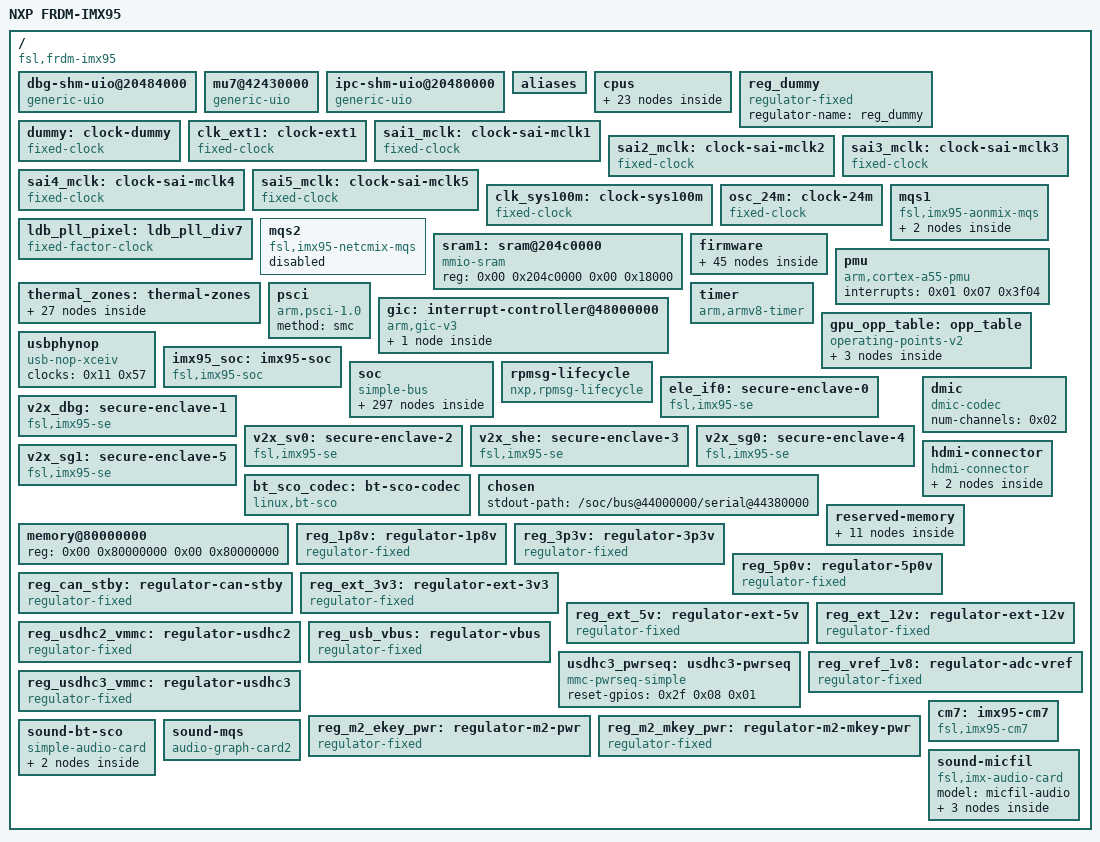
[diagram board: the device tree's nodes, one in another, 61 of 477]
/dts-v1/;

/ {
	interrupt-parent = <0x01>;
	#address-cells = <0x02>;
	#size-cells = <0x02>;
	compatible = "fsl,frdm-imx95", "fsl,imx95";
	model = "NXP FRDM-IMX95";

	dbg-shm-uio@20484000 {
		status = "okay";
		reg = <0x00 0x20484000 0x00 0x2000>;
		memory-region = <0x14f>;
		compatible = "generic-uio";
	};

	mu7@42430000 {
		status = "okay";
		interrupts = <0x00 0xea 0x04>;
		interrupt-parent = <0x01>;
		reg = <0x00 0x42430000 0x00 0x20000>;
		compatible = "generic-uio";
	};

	ipc-shm-uio@20480000 {
		status = "okay";
		reg = <0x00 0x20480000 0x00 0x4000>;
		memory-region = <0x14e>;
		compatible = "generic-uio";
	};

	aliases {
		gpio0 = "/soc/gpio@47400000";
		gpio1 = "/soc/gpio@43810000";
		gpio2 = "/soc/gpio@43820000";
		gpio3 = "/soc/gpio@43840000";
		gpio4 = "/soc/gpio@43850000";
		i2c0 = "/soc/bus@44000000/i2c@44340000";
		i2c1 = "/soc/bus@44000000/i2c@44350000";
		i2c2 = "/soc/bus@42000000/i2c@42530000";
		i2c3 = "/soc/bus@42000000/i2c@42540000";
		i2c4 = "/soc/bus@42000000/i2c@426b0000";
		i2c5 = "/soc/bus@42000000/i2c@426c0000";
		i2c6 = "/soc/bus@42000000/i2c@426d0000";
		i2c7 = "/soc/bus@42000000/i2c@426e0000";
		mmc0 = "/soc/bus@42800000/mmc@42850000";
		mmc1 = "/soc/bus@42800000/mmc@42860000";
		mmc2 = "/soc/bus@42800000/mmc@428b0000";
		serial0 = "/soc/bus@44000000/serial@44380000";
		serial1 = "/soc/bus@44000000/serial@44390000";
		serial2 = "/soc/bus@42000000/serial@42570000";
		serial3 = "/soc/bus@42000000/serial@42580000";
		serial4 = "/soc/bus@42000000/serial@42590000";
		serial5 = "/soc/bus@42000000/serial@425a0000";
		serial6 = "/soc/bus@42000000/serial@42690000";
		serial7 = "/soc/bus@42000000/serial@426a0000";
		ethernet0 = "/soc/system-controller@4cde0000/pcie@4ca00000/ethernet@0,0";
		ethernet1 = "/soc/system-controller@4cde0000/pcie@4ca00000/ethernet@8,0";
	};

	cpus {
		#address-cells = <0x01>;
		#size-cells = <0x00>;

		idle-states {
			entry-method = "psci";

			cpu_pd_wait: cpu-pd-wait {
				compatible = "arm,idle-state";
				arm,psci-suspend-param = <0x10033>;
				local-timer-stop;
				entry-latency-us = <0x2710>;
				exit-latency-us = <0x1b58>;
				min-residency-us = <0x6978>;
				wakeup-latency-us = <0x3a98>;
				phandle = <0x02>;
			};
		};

		A55_0: cpu@0 {
			device_type = "cpu";
			compatible = "arm,cortex-a55";
			reg = <0x00>;
			enable-method = "psci";
			#cooling-cells = <0x02>;
			cpu-idle-states = <0x02>;
			power-domains = <0x03 0x08>;
			power-domain-names = "perf";
			i-cache-size = <0x8000>;
			i-cache-line-size = <0x40>;
			i-cache-sets = <0x80>;
			d-cache-size = <0x8000>;
			d-cache-line-size = <0x40>;
			d-cache-sets = <0x80>;
			next-level-cache = <0x04>;
			phandle = <0x0b>;
		};

		A55_1: cpu@100 {
			device_type = "cpu";
			compatible = "arm,cortex-a55";
			reg = <0x100>;
			enable-method = "psci";
			#cooling-cells = <0x02>;
			cpu-idle-states = <0x02>;
			power-domains = <0x03 0x08>;
			power-domain-names = "perf";
			i-cache-size = <0x8000>;
			i-cache-line-size = <0x40>;
			i-cache-sets = <0x80>;
			d-cache-size = <0x8000>;
			d-cache-line-size = <0x40>;
			d-cache-sets = <0x80>;
			next-level-cache = <0x05>;
			phandle = <0x0c>;
		};

		A55_2: cpu@200 {
			device_type = "cpu";
			compatible = "arm,cortex-a55";
			reg = <0x200>;
			enable-method = "psci";
			#cooling-cells = <0x02>;
			cpu-idle-states = <0x02>;
			power-domains = <0x03 0x08>;
			power-domain-names = "perf";
			i-cache-size = <0x8000>;
			i-cache-line-size = <0x40>;
			i-cache-sets = <0x80>;
			d-cache-size = <0x8000>;
			d-cache-line-size = <0x40>;
			d-cache-sets = <0x80>;
			next-level-cache = <0x06>;
			phandle = <0x0d>;
		};

		A55_3: cpu@300 {
			device_type = "cpu";
			compatible = "arm,cortex-a55";
			reg = <0x300>;
			enable-method = "psci";
			#cooling-cells = <0x02>;
			cpu-idle-states = <0x02>;
			power-domains = <0x03 0x08>;
			power-domain-names = "perf";
			i-cache-size = <0x8000>;
			i-cache-line-size = <0x40>;
			i-cache-sets = <0x80>;
			d-cache-size = <0x8000>;
			d-cache-line-size = <0x40>;
			d-cache-sets = <0x80>;
			next-level-cache = <0x07>;
			phandle = <0x0e>;
		};

		A55_4: cpu@400 {
			device_type = "cpu";
			compatible = "arm,cortex-a55";
			reg = <0x400>;
			power-domains = <0x03 0x08>;
			power-domain-names = "perf";
			enable-method = "psci";
			#cooling-cells = <0x02>;
			cpu-idle-states = <0x02>;
			i-cache-size = <0x8000>;
			i-cache-line-size = <0x40>;
			i-cache-sets = <0x80>;
			d-cache-size = <0x8000>;
			d-cache-line-size = <0x40>;
			d-cache-sets = <0x80>;
			next-level-cache = <0x08>;
			phandle = <0x0f>;
		};

		A55_5: cpu@500 {
			device_type = "cpu";
			compatible = "arm,cortex-a55";
			reg = <0x500>;
			power-domains = <0x03 0x08>;
			power-domain-names = "perf";
			enable-method = "psci";
			#cooling-cells = <0x02>;
			cpu-idle-states = <0x02>;
			i-cache-size = <0x8000>;
			i-cache-line-size = <0x40>;
			i-cache-sets = <0x80>;
			d-cache-size = <0x8000>;
			d-cache-line-size = <0x40>;
			d-cache-sets = <0x80>;
			next-level-cache = <0x09>;
			phandle = <0x10>;
		};

		l2_cache_l0: l2-cache-l0 {
			compatible = "cache";
			cache-size = <0x10000>;
			cache-line-size = <0x40>;
			cache-sets = <0x100>;
			cache-level = <0x02>;
			cache-unified;
			next-level-cache = <0x0a>;
			phandle = <0x04>;
		};

		l2_cache_l1: l2-cache-l1 {
			compatible = "cache";
			cache-size = <0x10000>;
			cache-line-size = <0x40>;
			cache-sets = <0x100>;
			cache-level = <0x02>;
			cache-unified;
			next-level-cache = <0x0a>;
			phandle = <0x05>;
		};

		l2_cache_l2: l2-cache-l2 {
			compatible = "cache";
			cache-size = <0x10000>;
			cache-line-size = <0x40>;
			cache-sets = <0x100>;
			cache-level = <0x02>;
			cache-unified;
			next-level-cache = <0x0a>;
			phandle = <0x06>;
		};

		l2_cache_l3: l2-cache-l3 {
			compatible = "cache";
			cache-size = <0x10000>;
			cache-line-size = <0x40>;
			cache-sets = <0x100>;
			cache-level = <0x02>;
			cache-unified;
			next-level-cache = <0x0a>;
			phandle = <0x07>;
		};

		l2_cache_l4: l2-cache-l4 {
			compatible = "cache";
			cache-size = <0x10000>;
			cache-line-size = <0x40>;
			cache-sets = <0x100>;
			cache-level = <0x02>;
			cache-unified;
			next-level-cache = <0x0a>;
			phandle = <0x08>;
		};

		l2_cache_l5: l2-cache-l5 {
			compatible = "cache";
			cache-size = <0x10000>;
			cache-line-size = <0x40>;
			cache-sets = <0x100>;
			cache-level = <0x02>;
			cache-unified;
			next-level-cache = <0x0a>;
			phandle = <0x09>;
		};

		l3_cache: l3-cache {
			compatible = "cache";
			cache-size = <0x80000>;
			cache-line-size = <0x40>;
			cache-sets = <0x200>;
			cache-level = <0x03>;
			cache-unified;
			phandle = <0x0a>;
		};

		cpu-map {

			cluster0 {

				core0 {
					cpu = <0x0b>;
				};

				core1 {
					cpu = <0x0c>;
				};

				core2 {
					cpu = <0x0d>;
				};

				core3 {
					cpu = <0x0e>;
				};

				core4 {
					cpu = <0x0f>;
				};

				core5 {
					cpu = <0x10>;
				};
			};
		};
	};

	reg_dummy: reg_dummy {
		compatible = "regulator-fixed";
		regulator-name = "reg_dummy";
		phandle = <0xa8>;
	};

	dummy: clock-dummy {
		compatible = "fixed-clock";
		#clock-cells = <0x00>;
		clock-frequency = <0x00>;
		clock-output-names = "dummy";
		phandle = <0x37>;
	};

	clk_ext1: clock-ext1 {
		compatible = "fixed-clock";
		#clock-cells = <0x00>;
		clock-frequency = <0x7ed6b40>;
		clock-output-names = "clk_ext1";
		phandle = <0xa9>;
	};

	sai1_mclk: clock-sai-mclk1 {
		compatible = "fixed-clock";
		#clock-cells = <0x00>;
		clock-frequency = <0x00>;
		clock-output-names = "sai1_mclk";
		phandle = <0xaa>;
	};

	sai2_mclk: clock-sai-mclk2 {
		compatible = "fixed-clock";
		#clock-cells = <0x00>;
		clock-frequency = <0x00>;
		clock-output-names = "sai2_mclk";
		phandle = <0xab>;
	};

	sai3_mclk: clock-sai-mclk3 {
		compatible = "fixed-clock";
		#clock-cells = <0x00>;
		clock-frequency = <0x00>;
		clock-output-names = "sai3_mclk";
		phandle = <0xac>;
	};

	sai4_mclk: clock-sai-mclk4 {
		compatible = "fixed-clock";
		#clock-cells = <0x00>;
		clock-frequency = <0x00>;
		clock-output-names = "sai4_mclk";
		phandle = <0xad>;
	};

	sai5_mclk: clock-sai-mclk5 {
		compatible = "fixed-clock";
		#clock-cells = <0x00>;
		clock-frequency = <0x00>;
		clock-output-names = "sai5_mclk";
		phandle = <0xae>;
	};

	clk_sys100m: clock-sys100m {
		compatible = "fixed-clock";
		#clock-cells = <0x00>;
		clock-frequency = <0x5f5e100>;
		clock-output-names = "clk_sys100m";
		phandle = <0x78>;
	};

	osc_24m: clock-24m {
		compatible = "fixed-clock";
		#clock-cells = <0x00>;
		clock-frequency = <0x16e3600>;
		clock-output-names = "osc_24m";
		phandle = <0x49>;
	};

	ldb_pll_pixel: ldb_pll_div7 {
		#clock-cells = <0x00>;
		compatible = "fixed-factor-clock";
		clocks = <0x11 0x26>;
		clock-div = <0x07>;
		clock-mult = <0x01>;
		clock-output-names = "ldb_pll_div7";
		phandle = <0x73>;
	};

	mqs1: mqs1 {
		compatible = "fsl,imx95-aonmix-mqs";
		status = "okay";
		pinctrl-names = "default";
		pinctrl-0 = <0x12>;
		clocks = <0x11 0x3a>;
		clock-names = "mclk";
		#sound-dai-cells = <0x00>;
		phandle = <0xaf>;

		mqs1_port: port {
			dai-format = "left_j";
			playback-only;
			phandle = <0xb0>;

			mqs1_endpoint: endpoint {
				remote-endpoint = <0x13>;
				phandle = <0x4e>;
			};
		};
	};

	mqs2: mqs2 {
		compatible = "fsl,imx95-netcmix-mqs";
		status = "disabled";
		phandle = <0xb1>;
	};

	sram1: sram@204c0000 {
		compatible = "mmio-sram";
		reg = <0x00 0x204c0000 0x00 0x18000>;
		ranges = <0x00 0x00 0x204c0000 0x18000>;
		#address-cells = <0x01>;
		#size-cells = <0x01>;
		phandle = <0x8c>;
	};

	firmware {

		scmi {
			compatible = "arm,scmi";
			mboxes = <0x14 0x05 0x00 0x14 0x03 0x00 0x14 0x03 0x01 0x14 0x05 0x01>;
			shmem = <0x15 0x16>;
			#address-cells = <0x01>;
			#size-cells = <0x00>;
			arm,max-rx-timeout-ms = <0x1388>;
			max-rx-timeout-ms = <0x1388>;

			scmi_devpd: protocol@11 {
				reg = <0x11>;
				#power-domain-cells = <0x01>;
				phandle = <0x51>;
			};

			scmi_sys_power: protocol@12 {
				reg = <0x12>;
				phandle = <0xb2>;
			};

			scmi_perf: protocol@13 {
				reg = <0x13>;
				#power-domain-cells = <0x01>;
				phandle = <0x03>;
			};

			scmi_clk: protocol@14 {
				reg = <0x14>;
				#clock-cells = <0x01>;
				phandle = <0x11>;
			};

			scmi_sensor: protocol@15 {
				reg = <0x15>;
				#thermal-sensor-cells = <0x01>;
				phandle = <0x18>;
			};

			scmi_iomuxc: protocol@19 {
				reg = <0x19>;
				pinctrl-names = "default";
				pinctrl-0 = <0x17>;
				phandle = <0x48>;

				pinctrl_hog: hoggrp {
					fsl,pins = <0x190 0x394 0x00 0x05 0x00 0x31e>;
					phandle = <0x17>;
				};

				pinctrl_flexcan2: flexcan2grp {
					fsl,pins = <0x74 0x278 0x00 0x02 0x00 0x39e 0x7c 0x280 0x444 0x02 0x02 0x39e>;
					phandle = <0x35>;
				};

				pinctrl_flexcan5: flexcan5grp {
					fsl,pins = <0x68 0x26c 0x00 0x03 0x00 0x39e 0x6c 0x270 0x450 0x03 0x00 0x39e>;
					phandle = <0x39>;
				};

				pinctrl_lpi2c1: lpi2c1grp {
					fsl,pins = <0x1c0 0x3c4 0x00 0x00 0x00 0x40000b9e 0x1c4 0x3c8 0x00 0x00 0x00 0x40000b9e>;
					phandle = <0xb3>;
				};

				pinctrl_lpi2c2: lpi2c2grp {
					fsl,pins = <0x1c8 0x3cc 0x00 0x00 0x00 0x40000b9e 0x1cc 0x3d0 0x00 0x00 0x00 0x40000b9e>;
					phandle = <0x4b>;
				};

				pinctrl_lpi2c3: lpi2c3grp {
					fsl,pins = <0x80 0x284 0x504 0x11 0x01 0x40000b9e 0x84 0x288 0x500 0x11 0x01 0x40000b9e>;
					phandle = <0x29>;
				};

				pinctrl_lpi2c4: lpi2c4grp {
					fsl,pins = <0x88 0x28c 0x50c 0x11 0x01 0x40000b9e 0x8c 0x290 0x508 0x11 0x01 0x40000b9e>;
					phandle = <0x2e>;
				};

				pinctrl_pcal6524: pcal6524grp {
					fsl,pins = <0x98 0x29c 0x00 0x00 0x00 0x31e>;
					phandle = <0x4c>;
				};

				pinctrl_uart1: uart1grp {
					fsl,pins = <0x1d0 0x3d4 0x00 0x00 0x00 0x31e 0x1d4 0x3d8 0x00 0x00 0x00 0x31e>;
					phandle = <0x4d>;
				};

				pinctrl_uart5: uart5grp {
					fsl,pins = <0x0c 0x210 0x574 0x06 0x00 0x31e 0x00 0x204 0x570 0x06 0x00 0x31e 0x04 0x208 0x00 0x06 0x00 0x31e 0x08 0x20c 0x56c 0x06 0x00 0x31e>;
					phandle = <0x34>;
				};

				pinctrl_enetc0: enetc0grp {
					fsl,pins = <0xc0 0x2c4 0x00 0x00 0x00 0x50e 0xc4 0x2c8 0x00 0x00 0x00 0x50e 0xc8 0x2cc 0x00 0x00 0x00 0x50e 0xcc 0x2d0 0x00 0x00 0x00 0x50e 0xd0 0x2d4 0x00 0x00 0x00 0x57e 0xd4 0x2d8 0x00 0x00 0x00 0x58e 0xd8 0x2dc 0x00 0x00 0x00 0x57e 0xdc 0x2e0 0x00 0x00 0x00 0x58e 0xe0 0x2e4 0x00 0x00 0x00 0x57e 0xe4 0x2e8 0x00 0x00 0x00 0x57e 0xe8 0x2ec 0x00 0x00 0x00 0x57e 0xec 0x2f0 0x00 0x00 0x00 0x57e>;
					phandle = <0x83>;
				};

				pinctrl_enetc1: enetc1grp {
					fsl,pins = <0xf8 0x2fc 0x00 0x00 0x00 0x50e 0xfc 0x300 0x00 0x00 0x00 0x50e 0x100 0x304 0x00 0x00 0x00 0x50e 0x104 0x308 0x00 0x00 0x00 0x50e 0x108 0x30c 0x00 0x00 0x00 0x57e 0x10c 0x310 0x00 0x00 0x00 0x58e 0x110 0x314 0x00 0x00 0x00 0x57e 0x114 0x318 0x00 0x00 0x00 0x58e 0x118 0x31c 0x00 0x00 0x00 0x57e 0x11c 0x320 0x00 0x00 0x00 0x57e 0x120 0x324 0x00 0x00 0x00 0x57e 0x124 0x328 0x00 0x00 0x00 0x57e>;
					phandle = <0x86>;
				};

				pinctrl_emdio: emdiogrp {
					fsl,pins = <0xf0 0x2f4 0x424 0x00 0x01 0x50e 0xf4 0x2f8 0x428 0x00 0x01 0x90e>;
					phandle = <0x89>;
				};

				pinctrl_mipi_dsi_csi: mipidsigrp {
					fsl,pins = <0xa8 0x2ac 0x00 0x05 0x00 0x31e>;
					phandle = <0xb4>;
				};

				pinctrl_ekey_pwr: ekeypwrgrp {
					fsl,pins = <0x19c 0x3a0 0x00 0x05 0x00 0x31e>;
					phandle = <0x99>;
				};

				pinctrl_mkey_pwr: mkeypwrgrp {
					fsl,pins = <0x198 0x39c 0x00 0x05 0x00 0x31e>;
					phandle = <0x9a>;
				};

				pinctrl_mqs1: mqs1grp {
					fsl,pins = <0x1ec 0x3f0 0x00 0x04 0x00 0x31e 0x1f8 0x3fc 0x00 0x04 0x00 0x31e>;
					phandle = <0x12>;
				};

				pinctrl_pcie0: pcie0grp {
					fsl,pins = <0x90 0x294 0x00 0x01 0x00 0x40000b1e 0x94 0x298 0x00 0x00 0x00 0x31e>;
					phandle = <0x7f>;
				};

				pinctrl_pdm: pdmgrp {
					fsl,pins = <0x1e0 0x3e4 0x00 0x00 0x00 0x31e 0x1e4 0x3e8 0x40c 0x00 0x00 0x31e>;
					phandle = <0x4f>;
				};

				pinctrl_ptn5110: ptn5110grp {
					fsl,pins = <0x17c 0x380 0x00 0x05 0x00 0x31e>;
					phandle = <0x2b>;
				};

				pinctrl_sai5: sai5grp {
					fsl,pins = <0x180 0x384 0x00 0x01 0x00 0x31e 0x184 0x388 0x5c4 0x01 0x01 0x31e 0x188 0x38c 0x5c0 0x01 0x01 0x31e 0x18c 0x390 0x5ac 0x01 0x01 0x31e>;
					phandle = <0x38>;
				};

				pinctrl_usdhc1: usdhc1grp {
					fsl,pins = <0x128 0x32c 0x00 0x00 0x00 0x158e 0x12c 0x330 0x00 0x00 0x00 0x138e 0x130 0x334 0x00 0x00 0x00 0x138e 0x134 0x338 0x00 0x00 0x00 0x138e 0x138 0x33c 0x00 0x00 0x00 0x138e 0x13c 0x340 0x00 0x00 0x00 0x138e 0x140 0x344 0x00 0x00 0x00 0x138e 0x144 0x348 0x00 0x00 0x00 0x138e 0x148 0x34c 0x00 0x00 0x00 0x138e 0x14c 0x350 0x00 0x00 0x00 0x138e 0x150 0x354 0x00 0x00 0x00 0x158e>;
					phandle = <0x3a>;
				};

				pinctrl_usdhc1_100mhz: usdhc1-100mhzgrp {
					fsl,pins = <0x128 0x32c 0x00 0x00 0x00 0x158e 0x12c 0x330 0x00 0x00 0x00 0x138e 0x130 0x334 0x00 0x00 0x00 0x138e 0x134 0x338 0x00 0x00 0x00 0x138e 0x138 0x33c 0x00 0x00 0x00 0x138e 0x13c 0x340 0x00 0x00 0x00 0x138e 0x140 0x344 0x00 0x00 0x00 0x138e 0x144 0x348 0x00 0x00 0x00 0x138e 0x148 0x34c 0x00 0x00 0x00 0x138e 0x14c 0x350 0x00 0x00 0x00 0x138e 0x150 0x354 0x00 0x00 0x00 0x158e>;
					phandle = <0x3b>;
				};

				pinctrl_usdhc1_200mhz: usdhc1-200mhzgrp {
					fsl,pins = <0x128 0x32c 0x00 0x00 0x00 0x15fe 0x12c 0x330 0x00 0x00 0x00 0x13fe 0x130 0x334 0x00 0x00 0x00 0x13fe 0x134 0x338 0x00 0x00 0x00 0x13fe 0x138 0x33c 0x00 0x00 0x00 0x13fe 0x13c 0x340 0x00 0x00 0x00 0x13fe 0x140 0x344 0x00 0x00 0x00 0x13fe 0x144 0x348 0x00 0x00 0x00 0x13fe 0x148 0x34c 0x00 0x00 0x00 0x13fe 0x14c 0x350 0x00 0x00 0x00 0x13fe 0x150 0x354 0x00 0x00 0x00 0x15fe>;
					phandle = <0x3c>;
				};

				pinctrl_reg_usdhc2_vmmc: regusdhc2vmmcgrp {
					fsl,pins = <0x1bc 0x3c0 0x00 0x05 0x00 0x31e>;
					phandle = <0x97>;
				};

				pinctrl_reg_ext_pwr: regextpwrengrp {
					fsl,pins = <0x194 0x398 0x00 0x05 0x00 0x31e>;
					phandle = <0xb5>;
				};

				pinctrl_lpspi3: lpspi3grp {
					fsl,pins = <0x30 0x234 0x00 0x00 0x00 0x39e 0x34 0x238 0x00 0x01 0x00 0x39e 0x38 0x23c 0x00 0x01 0x00 0x39e 0x3c 0x240 0x00 0x01 0x00 0x39e>;
					phandle = <0x32>;
				};

				pinctrl_usdhc2_gpio: usdhc2gpiogrp {
					fsl,pins = <0x1a0 0x3a4 0x00 0x05 0x00 0x31e>;
					phandle = <0x3e>;
				};

				pinctrl_usdhc2: usdhc2grp {
					fsl,pins = <0x1a4 0x3a8 0x00 0x00 0x00 0x158e 0x1a8 0x3ac 0x00 0x00 0x00 0x138e 0x1ac 0x3b0 0x00 0x00 0x00 0x138e 0x1b0 0x3b4 0x00 0x00 0x00 0x138e 0x1b4 0x3b8 0x00 0x00 0x00 0x138e 0x1b8 0x3bc 0x00 0x00 0x00 0x138e 0x154 0x358 0x00 0x00 0x00 0x51e>;
					phandle = <0x3d>;
				};

				pinctrl_usdhc2_100mhz: usdhc2-100mhzgrp {
					fsl,pins = <0x1a4 0x3a8 0x00 0x00 0x00 0x158e 0x1a8 0x3ac 0x00 0x00 0x00 0x138e 0x1ac 0x3b0 0x00 0x00 0x00 0x138e 0x1b0 0x3b4 0x00 0x00 0x00 0x138e 0x1b4 0x3b8 0x00 0x00 0x00 0x138e 0x1b8 0x3bc 0x00 0x00 0x00 0x138e 0x154 0x358 0x00 0x00 0x00 0x51e>;
					phandle = <0x3f>;
				};

				pinctrl_usdhc2_200mhz: usdhc2-200mhzgrp {
					fsl,pins = <0x1a4 0x3a8 0x00 0x00 0x00 0x158e 0x1a8 0x3ac 0x00 0x00 0x00 0x138e 0x1ac 0x3b0 0x00 0x00 0x00 0x138e 0x1b0 0x3b4 0x00 0x00 0x00 0x138e 0x1b4 0x3b8 0x00 0x00 0x00 0x138e 0x1b8 0x3bc 0x00 0x00 0x00 0x138e 0x154 0x358 0x00 0x00 0x00 0x51e>;
					phandle = <0x40>;
				};

				pinctrl_usdhc3: usdhc3grp {
					fsl,pins = <0x158 0x35c 0x5c8 0x00 0x01 0x158e 0x15c 0x360 0x5cc 0x00 0x01 0x138e 0x160 0x364 0x5d0 0x00 0x01 0x138e 0x164 0x368 0x5d4 0x00 0x01 0x138e 0x168 0x36c 0x5d8 0x00 0x01 0x138e 0x16c 0x370 0x5dc 0x00 0x01 0x138e>;
					phandle = <0x43>;
				};

				pinctrl_usdhc3_100mhz: usdhc3-100mhzgrp {
					fsl,pins = <0x158 0x35c 0x5c8 0x00 0x01 0x158e 0x15c 0x360 0x5cc 0x00 0x01 0x138e 0x160 0x364 0x5d0 0x00 0x01 0x138e 0x164 0x368 0x5d4 0x00 0x01 0x138e 0x168 0x36c 0x5d8 0x00 0x01 0x138e 0x16c 0x370 0x5dc 0x00 0x01 0x138e>;
					phandle = <0x44>;
				};

				pinctrl_usdhc3_200mhz: usdhc3-200mhzgrp {
					fsl,pins = <0x158 0x35c 0x5c8 0x00 0x01 0x15fe 0x15c 0x360 0x5cc 0x00 0x01 0x13fe 0x160 0x364 0x5d0 0x00 0x01 0x13fe 0x164 0x368 0x5d4 0x00 0x01 0x13fe 0x168 0x36c 0x5d8 0x00 0x01 0x13fe 0x16c 0x370 0x5dc 0x00 0x01 0x13fe>;
					phandle = <0x45>;
				};
			};

			scmi_lmm: protocol@80 {
				reg = <0x80>;
				phandle = <0xb6>;
			};

			scmi_bbm: protocol@81 {
				reg = <0x81>;
				phandle = <0xb7>;
			};

			scmi_cpu: protocol@82 {
				reg = <0x82>;
				phandle = <0xb8>;
			};

			scmi_misc: protocol@84 {
				reg = <0x84>;
				nxp,ctrl-ids = <0x8000 0x01 0x8001 0x01 0x8002 0x01 0x8003 0x01 0x8004 0x01>;
				phandle = <0xb9>;
			};
		};
	};

	pmu {
		compatible = "arm,cortex-a55-pmu";
		interrupts = <0x01 0x07 0x3f04>;
	};

	thermal_zones: thermal-zones {
		phandle = <0xba>;

		a55-thermal {
			polling-delay-passive = <0xfa>;
			polling-delay = <0x7d0>;
			thermal-sensors = <0x18 0x01>;

			trips {

				cpu_alert0: trip0 {
					temperature = <0x19a28>;
					hysteresis = <0x7d0>;
					type = "passive";
					phandle = <0x19>;
				};

				cpu_crit0: trip1 {
					temperature = <0x1e848>;
					hysteresis = <0x7d0>;
					type = "critical";
					phandle = <0xbb>;
				};
			};

			cooling-maps {

				map0 {
					trip = <0x19>;
					cooling-device = <0x0b 0xffffffff 0xffffffff 0x0c 0xffffffff 0xffffffff 0x0d 0xffffffff 0xffffffff 0x0e 0xffffffff 0xffffffff 0x0f 0xffffffff 0xffffffff 0x10 0xffffffff 0xffffffff>;
				};
			};
		};

		ana-thermal {
			polling-delay-passive = <0xfa>;
			polling-delay = <0x7d0>;
			thermal-sensors = <0x18 0x00>;

			trips {

				ana_alert: trip0 {
					temperature = <0x19a28>;
					hysteresis = <0x7d0>;
					type = "passive";
					phandle = <0x1a>;
				};

				ana_crit0: trip1 {
					temperature = <0x1e848>;
					hysteresis = <0x7d0>;
					type = "critical";
					phandle = <0x1d>;
				};
			};

			cooling-maps {

				map0 {
					trip = <0x1a>;
					cooling-device = <0x0b 0xffffffff 0xffffffff 0x0c 0xffffffff 0xffffffff 0x0d 0xffffffff 0xffffffff 0x0e 0xffffffff 0xffffffff 0x0f 0xffffffff 0xffffffff 0x10 0xffffffff 0xffffffff 0x1b 0xffffffff 0xffffffff 0x1c 0xffffffff 0xffffffff>;
				};

				map1 {
					trip = <0x1d>;
					cooling-device = <0x1b 0xffffffff 0x01>;
				};
			};
		};

		pf09 {
			polling-delay-passive = <0xfa>;
			polling-delay = <0x7d0>;
			thermal-sensors = <0x18 0x02>;

			trips {

				pf09_alert: trip0 {
					temperature = <0x222e0>;
					hysteresis = <0x7d0>;
					type = "passive";
					phandle = <0xbc>;
				};

				pf09_crit: trip1 {
					temperature = <0x25d78>;
					hysteresis = <0x7d0>;
					type = "critical";
					phandle = <0xbd>;
				};
			};
		};

		pf53_arm {
			polling-delay-passive = <0xfa>;
			polling-delay = <0x7d0>;
			thermal-sensors = <0x18 0x04>;

			trips {

				pf5301_alert: trip0 {
					temperature = <0x222e0>;
					hysteresis = <0x7d0>;
					type = "passive";
					phandle = <0x1e>;
				};

				pf5301_crit: trip1 {
					temperature = <0x25d78>;
					hysteresis = <0x7d0>;
					type = "critical";
					phandle = <0xbe>;
				};
			};

			cooling-maps {

				map0 {
					trip = <0x1e>;
					cooling-device = <0x0b 0xffffffff 0xffffffff 0x0c 0xffffffff 0xffffffff 0x0d 0xffffffff 0xffffffff 0x0e 0xffffffff 0xffffffff 0x0f 0xffffffff 0xffffffff 0x10 0xffffffff 0xffffffff>;
				};
			};
		};

		pf53_soc {
			polling-delay-passive = <0xfa>;
			polling-delay = <0x7d0>;
			thermal-sensors = <0x18 0x03>;

			trips {

				pf5302_alert: trip0 {
					temperature = <0x222e0>;
					hysteresis = <0x7d0>;
					type = "passive";
					phandle = <0xbf>;
				};

				pf5302_crit: trip1 {
					temperature = <0x25d78>;
					hysteresis = <0x7d0>;
					type = "critical";
					phandle = <0xc0>;
				};
			};
		};
	};

	psci {
		compatible = "arm,psci-1.0";
		method = "smc";
	};

	timer {
		compatible = "arm,armv8-timer";
		interrupts = <0x01 0x0d 0x3f08 0x01 0x0e 0x3f08 0x01 0x0b 0x3f08 0x01 0x0a 0x3f08>;
		clock-frequency = <0x16e3600>;
		arm,no-tick-in-suspend;
		interrupt-parent = <0x01>;
	};

	gic: interrupt-controller@48000000 {
		compatible = "arm,gic-v3";
		reg = <0x00 0x48000000 0x00 0x10000 0x00 0x48060000 0x00 0xc0000>;
		#address-cells = <0x02>;
		#size-cells = <0x02>;
		#interrupt-cells = <0x03>;
		interrupt-controller;
		interrupts = <0x01 0x09 0x04>;
		interrupt-parent = <0x01>;
		dma-noncoherent;
		ranges;
		phandle = <0x01>;

		its: msi-controller@48040000 {
			compatible = "arm,gic-v3-its";
			reg = <0x00 0x48040000 0x00 0x20000>;
			msi-controller;
			#msi-cells = <0x01>;
			dma-noncoherent;
			phandle = <0x7e>;
		};
	};

	gpu_opp_table: opp_table {
		compatible = "operating-points-v2", "operating-points-v2-mali";
		phandle = <0x8a>;

		opp-500000000 {
			opp-hz = <0x00 0x1dcd6500>;
			opp-hz-real = <0x00 0x1dcd6500>;
			opp-microvolt = <0xe09c0>;
		};

		opp-800000000 {
			opp-hz = <0x00 0x2faf0800>;
			opp-hz-real = <0x00 0x2faf0800>;
			opp-microvolt = <0xe09c0>;
		};

		opp-1000000000 {
			opp-hz = <0x00 0x3b9aca00>;
			opp-hz-real = <0x00 0x3b9aca00>;
			opp-microvolt = <0xe09c0>;
		};
	};

	usbphynop: usbphynop {
		compatible = "usb-nop-xceiv";
		clocks = <0x11 0x57>;
		clock-names = "main_clk";
		#phy-cells = <0x00>;
		phandle = <0x7a>;
	};

	imx95_soc: imx95-soc {
		compatible = "fsl,imx95-soc";
		phandle = <0xc1>;
	};

	soc {
		compatible = "simple-bus";
		#address-cells = <0x02>;
		#size-cells = <0x02>;
		ranges;

		etm0: etm@40840000 {
			compatible = "arm,coresight-etm4x", "arm,primecell";
			reg = <0x00 0x40840000 0x00 0x10000>;
			arm,primecell-periphid = <0xbb95d>;
			cpu = <0x0b>;
			clocks = <0x11 0x48>;
			clock-names = "apb_pclk";
			status = "disabled";
			phandle = <0xc2>;

			out-ports {

				port {

					etm0_out_port: endpoint {
						remote-endpoint = <0x1f>;
						phandle = <0x20>;
					};
				};
			};
		};

		funnel0: funnel {
			compatible = "arm,coresight-static-funnel";
			status = "disabled";
			phandle = <0xc3>;

			in-ports {

				port {

					ca_funnel_in_port0: endpoint {
						remote-endpoint = <0x20>;
						phandle = <0x1f>;
					};
				};
			};

			out-ports {

				port {

					ca_funnel_out_port0: endpoint {
						remote-endpoint = <0x21>;
						phandle = <0x22>;
					};
				};
			};
		};

		funnel1: funnel-sys {
			compatible = "arm,coresight-static-funnel";
			status = "disabled";
			phandle = <0xc4>;

			in-ports {

				port {

					hugo_funnel_in_port0: endpoint {
						remote-endpoint = <0x22>;
						phandle = <0x21>;
					};
				};
			};

			out-ports {

				port {

					hugo_funnel_out_port0: endpoint {
						remote-endpoint = <0x23>;
						phandle = <0x24>;
					};
				};
			};
		};

		etf: etf@41030000 {
			compatible = "arm,coresight-tmc", "arm,primecell";
			reg = <0x00 0x41030000 0x00 0x1000>;
			clocks = <0x11 0x48>;
			clock-names = "apb_pclk";
			status = "disabled";
			phandle = <0xc5>;

			in-ports {

				port {

					etf_in_port: endpoint {
						remote-endpoint = <0x24>;
						phandle = <0x23>;
					};
				};
			};

			out-ports {

				port {

					etf_out_port: endpoint {
						remote-endpoint = <0x25>;
						phandle = <0x26>;
					};
				};
			};
		};

		etr: etr@41040000 {
			compatible = "arm,coresight-tmc", "arm,primecell";
			reg = <0x00 0x41040000 0x00 0x1000>;
			clocks = <0x11 0x48>;
			clock-names = "apb_pclk";
			status = "disabled";
			phandle = <0xc6>;

			in-ports {

				port {

					etr_in_port: endpoint {
						remote-endpoint = <0x26>;
						phandle = <0x25>;
					};
				};
			};
		};

		aips2: bus@42000000 {
			compatible = "fsl,aips-bus", "simple-bus";
			reg = <0x00 0x42000000 0x00 0x800000>;
			ranges = <0x42000000 0x00 0x42000000 0x8000000 0x28000000 0x00 0x28000000 0x10000000>;
			#address-cells = <0x01>;
			#size-cells = <0x01>;
			phandle = <0xc7>;

			edma2: dma-controller@42000000 {
				compatible = "fsl,imx95-edma5";
				reg = <0x42000000 0x210000>;
				#dma-cells = <0x03>;
				dma-channels = <0x40>;
				dma-channel-mask = <0x03>;
				interrupts = <0x00 0x80 0x04 0x00 0x80 0x04 0x00 0x81 0x04 0x00 0x81 0x04 0x00 0x82 0x04 0x00 0x82 0x04 0x00 0x83 0x04 0x00 0x83 0x04 0x00 0x84 0x04 0x00 0x84 0x04 0x00 0x85 0x04 0x00 0x85 0x04 0x00 0x86 0x04 0x00 0x86 0x04 0x00 0x87 0x04 0x00 0x87 0x04 0x00 0x88 0x04 0x00 0x88 0x04 0x00 0x89 0x04 0x00 0x89 0x04 0x00 0x8a 0x04 0x00 0x8a 0x04 0x00 0x8b 0x04 0x00 0x8b 0x04 0x00 0x8c 0x04 0x00 0x8c 0x04 0x00 0x8d 0x04 0x00 0x8d 0x04 0x00 0x8e 0x04 0x00 0x8e 0x04 0x00 0x8f 0x04 0x00 0x8f 0x04 0x00 0x90 0x04 0x00 0x90 0x04 0x00 0x91 0x04 0x00 0x91 0x04 0x00 0x92 0x04 0x00 0x92 0x04 0x00 0x93 0x04 0x00 0x93 0x04 0x00 0x94 0x04 0x00 0x94 0x04 0x00 0x95 0x04 0x00 0x95 0x04 0x00 0x96 0x04 0x00 0x96 0x04 0x00 0x97 0x04 0x00 0x97 0x04 0x00 0x98 0x04 0x00 0x98 0x04 0x00 0x99 0x04 0x00 0x99 0x04 0x00 0x9a 0x04 0x00 0x9a 0x04 0x00 0x9b 0x04 0x00 0x9b 0x04 0x00 0x9c 0x04 0x00 0x9c 0x04 0x00 0x9d 0x04 0x00 0x9d 0x04 0x00 0x9e 0x04 0x00 0x9e 0x04 0x00 0x9f 0x04 0x00 0x9f 0x04 0x00 0x7f 0x04>;
				clocks = <0x11 0x77>;
				clock-names = "dma";
				phandle = <0x28>;
			};

			edma3: dma-controller@42210000 {
				compatible = "fsl,imx95-edma5";
				reg = <0x42210000 0x210000>;
				#dma-cells = <0x03>;
				dma-channels = <0x40>;
				interrupts = <0x00 0x100 0x04 0x00 0x100 0x04 0x00 0x101 0x04 0x00 0x101 0x04 0x00 0x102 0x04 0x00 0x102 0x04 0x00 0x103 0x04 0x00 0x103 0x04 0x00 0x104 0x04 0x00 0x104 0x04 0x00 0x105 0x04 0x00 0x105 0x04 0x00 0x106 0x04 0x00 0x106 0x04 0x00 0x107 0x04 0x00 0x107 0x04 0x00 0x108 0x04 0x00 0x108 0x04 0x00 0x109 0x04 0x00 0x109 0x04 0x00 0x10a 0x04 0x00 0x10a 0x04 0x00 0x10b 0x04 0x00 0x10b 0x04 0x00 0x10c 0x04 0x00 0x10c 0x04 0x00 0x10d 0x04 0x00 0x10d 0x04 0x00 0x10e 0x04 0x00 0x10e 0x04 0x00 0x10f 0x04 0x00 0x10f 0x04 0x00 0x110 0x04 0x00 0x110 0x04 0x00 0x111 0x04 0x00 0x111 0x04 0x00 0x112 0x04 0x00 0x112 0x04 0x00 0x113 0x04 0x00 0x113 0x04 0x00 0x114 0x04 0x00 0x114 0x04 0x00 0x115 0x04 0x00 0x115 0x04 0x00 0x116 0x04 0x00 0x116 0x04 0x00 0x117 0x04 0x00 0x117 0x04 0x00 0x118 0x04 0x00 0x118 0x04 0x00 0x119 0x04 0x00 0x119 0x04 0x00 0x11a 0x04 0x00 0x11a 0x04 0x00 0x11b 0x04 0x00 0x11b 0x04 0x00 0x11c 0x04 0x00 0x11c 0x04 0x00 0x11d 0x04 0x00 0x11d 0x04 0x00 0x11e 0x04 0x00 0x11e 0x04 0x00 0x11f 0x04 0x00 0x11f 0x04 0x00 0xfa 0x04>;
				clocks = <0x11 0x77>;
				clock-names = "dma";
				dma-coherent;
				iommus = <0x27 0x00>;
				phandle = <0xc8>;
			};

			mu7: mailbox@42430000 {
				compatible = "fsl,imx95-mu";
				reg = <0x42430000 0x10000>;
				interrupts = <0x00 0xea 0x04>;
				clocks = <0x11 0x77>;
				#mbox-cells = <0x02>;
				status = "disabled";
				phandle = <0x9b>;
			};

			wdog3: watchdog@42490000 {
				compatible = "fsl,imx93-wdt";
				reg = <0x42490000 0x10000>;
				interrupts = <0x00 0x4d 0x04>;
				clocks = <0x11 0x77>;
				timeout-sec = <0x28>;
				status = "okay";
				phandle = <0xc9>;
			};

			tpm3: pwm@424e0000 {
				compatible = "fsl,imx7ulp-pwm";
				reg = <0x424e0000 0x1000>;
				clocks = <0x11 0x77>;
				#pwm-cells = <0x03>;
				status = "disabled";
				phandle = <0xca>;
			};

			tpm4: pwm@424f0000 {
				compatible = "fsl,imx7ulp-pwm";
				reg = <0x424f0000 0x1000>;
				clocks = <0x11 0x99>;
				#pwm-cells = <0x03>;
				status = "disabled";
				phandle = <0xcb>;
			};

			tpm5: pwm@42500000 {
				compatible = "fsl,imx7ulp-pwm";
				reg = <0x42500000 0x1000>;
				clocks = <0x11 0x9a>;
				#pwm-cells = <0x03>;
				status = "disabled";
				phandle = <0xcc>;
			};

			tpm6: pwm@42510000 {
				compatible = "fsl,imx7ulp-pwm";
				reg = <0x42510000 0x1000>;
				clocks = <0x11 0x9b>;
				#pwm-cells = <0x03>;
				status = "disabled";
				phandle = <0xcd>;
			};

			i3c2: i3c@42520000 {
				compatible = "nxp,imx95-i3c", "silvaco,i3c-master-v1";
				reg = <0x42520000 0x10000>;
				interrupts = <0x00 0x39 0x04>;
				#address-cells = <0x03>;
				#size-cells = <0x00>;
				clocks = <0x11 0x77 0x11 0x80>;
				clock-names = "pclk", "fast_clk";
				status = "disabled";
				phandle = <0xce>;
			};

			lpi2c3: i2c@42530000 {
				compatible = "fsl,imx95-lpi2c", "fsl,imx7ulp-lpi2c";
				reg = <0x42530000 0x10000>;
				interrupts = <0x00 0x3a 0x04>;
				clocks = <0x11 0x81 0x11 0x77>;
				clock-names = "per", "ipg";
				#address-cells = <0x01>;
				#size-cells = <0x00>;
				dmas = <0x28 0x08 0x00 0x00 0x28 0x09 0x00 0x01>;
				dma-names = "tx", "rx";
				status = "okay";
				clock-frequency = <0x61a80>;
				pinctrl-names = "default";
				pinctrl-0 = <0x29>;
				phandle = <0xcf>;

				ptn5110: tcpc@50 {
					compatible = "nxp,ptn5110";
					reg = <0x50>;
					interrupt-parent = <0x2a>;
					interrupts = <0x03 0x08>;
					pinctrl-names = "default";
					pinctrl-0 = <0x2b>;
					phandle = <0xd0>;

					typec_con: connector {
						compatible = "usb-c-connector";
						label = "USB-C";
						power-role = "dual";
						data-role = "dual";
						try-power-role = "sink";
						source-pdos = <0x401912c>;
						sink-pdos = <0x401912c 0x9901912c>;
						op-sink-microwatt = <0xe4e1c0>;
						self-powered;
						phandle = <0xd1>;

						ports {
							#address-cells = <0x01>;
							#size-cells = <0x00>;

							port@0 {
								reg = <0x00>;

								typec_con_hs: endpoint {
									remote-endpoint = <0x2c>;
									phandle = <0x77>;
								};
							};

							port@1 {
								reg = <0x01>;

								typec_con_ss: endpoint {
									remote-endpoint = <0x2d>;
									phandle = <0x79>;
								};
							};
						};
					};
				};
			};

			lpi2c4: i2c@42540000 {
				compatible = "fsl,imx95-lpi2c", "fsl,imx7ulp-lpi2c";
				reg = <0x42540000 0x10000>;
				interrupts = <0x00 0x3b 0x04>;
				clocks = <0x11 0x82 0x11 0x77>;
				clock-names = "per", "ipg";
				#address-cells = <0x01>;
				#size-cells = <0x00>;
				dmas = <0x28 0x0a 0x00 0x00 0x28 0x0b 0x00 0x01>;
				dma-names = "tx", "rx";
				status = "okay";
				clock-frequency = <0x61a80>;
				pinctrl-names = "default";
				pinctrl-0 = <0x2e>;
				phandle = <0xd2>;

				pca9632: pca9632@62 {
					compatible = "nxp,pca9632";
					#address-cells = <0x01>;
					#size-cells = <0x00>;
					reg = <0x62>;
					nxp,inverted-out;
					phandle = <0xd3>;

					led_backlight0: led@0 {
						reg = <0x00>;
						function = "backlight";
						color = <0x00>;
						function-enumerator = <0x00>;
						phandle = <0xd4>;
					};

					led_backlight1: led@1 {
						reg = <0x01>;
						function = "backlight";
						color = <0x00>;
						function-enumerator = <0x01>;
						phandle = <0xd5>;
					};
				};

				bridge@4c {
					compatible = "ite,it6263";
					reg = <0x4c>;
					reset-gpios = <0x2f 0x17 0x01>;

					ports {
						#address-cells = <0x01>;
						#size-cells = <0x00>;

						port@0 {
							reg = <0x00>;

							it6263_in: endpoint {
								remote-endpoint = <0x30>;
								phandle = <0x6d>;
							};
						};

						port@1 {
							reg = <0x01>;

							it6263_out: endpoint {
								remote-endpoint = <0x31>;
								phandle = <0x95>;
							};
						};
					};
				};
			};

			lpspi3: spi@42550000 {
				#address-cells = <0x01>;
				#size-cells = <0x00>;
				compatible = "fsl,imx95-spi", "fsl,imx7ulp-spi";
				reg = <0x42550000 0x10000>;
				interrupts = <0x00 0x3d 0x04>;
				clocks = <0x11 0x87 0x11 0x77>;
				clock-names = "per", "ipg";
				dmas = <0x28 0x0c 0x00 0x00 0x28 0x0d 0x00 0x01>;
				dma-names = "tx", "rx";
				status = "okay";
				pinctrl-names = "default";
				pinctrl-0 = <0x32>;
				cs-gpios = <0x33 0x08 0x01>;
				phandle = <0xd6>;

				spidev0: spi@0 {
					reg = <0x00>;
					compatible = "lwn,bk4";
					spi-max-frequency = <0xf4240>;
					phandle = <0xd7>;
				};
			};

			lpspi4: spi@42560000 {
				#address-cells = <0x01>;
				#size-cells = <0x00>;
				compatible = "fsl,imx95-spi", "fsl,imx7ulp-spi";
				reg = <0x42560000 0x10000>;
				interrupts = <0x00 0x3e 0x04>;
				clocks = <0x11 0x88 0x11 0x77>;
				clock-names = "per", "ipg";
				dmas = <0x28 0x0e 0x00 0x00 0x28 0x0f 0x00 0x01>;
				dma-names = "tx", "rx";
				status = "disabled";
				phandle = <0xd8>;
			};

			lpuart3: serial@42570000 {
				compatible = "fsl,imx95-lpuart", "fsl,imx8ulp-lpuart", "fsl,imx7ulp-lpuart";
				reg = <0x42570000 0x1000>;
				interrupts = <0x00 0x40 0x04>;
				clocks = <0x11 0x8e>;
				clock-names = "ipg";
				dmas = <0x28 0x12 0x00 0x01 0x28 0x11 0x00 0x00>;
				dma-names = "rx", "tx";
				status = "disabled";
				phandle = <0xd9>;
			};

			lpuart4: serial@42580000 {
				compatible = "fsl,imx95-lpuart", "fsl,imx8ulp-lpuart", "fsl,imx7ulp-lpuart";
				reg = <0x42580000 0x1000>;
				interrupts = <0x00 0x41 0x04>;
				clocks = <0x11 0x8f>;
				clock-names = "ipg";
				dmas = <0x28 0x14 0x00 0x01 0x28 0x13 0x00 0x00>;
				dma-names = "rx", "tx";
				status = "disabled";
				phandle = <0xda>;
			};

			lpuart5: serial@42590000 {
				compatible = "fsl,imx95-lpuart", "fsl,imx8ulp-lpuart", "fsl,imx7ulp-lpuart";
				reg = <0x42590000 0x1000>;
				interrupts = <0x00 0x42 0x04>;
				clocks = <0x11 0x90>;
				clock-names = "ipg";
				dmas = <0x28 0x16 0x00 0x01 0x28 0x15 0x00 0x00>;
				dma-names = "rx", "tx";
				status = "okay";
				pinctrl-names = "default";
				pinctrl-0 = <0x34>;
				phandle = <0xdb>;

				bluetooth {
					compatible = "nxp,88w8987-bt";
				};
			};

			lpuart6: serial@425a0000 {
				compatible = "fsl,imx95-lpuart", "fsl,imx8ulp-lpuart", "fsl,imx7ulp-lpuart";
				reg = <0x425a0000 0x1000>;
				interrupts = <0x00 0x43 0x04>;
				clocks = <0x11 0x91>;
				clock-names = "ipg";
				dmas = <0x28 0x18 0x00 0x01 0x28 0x17 0x00 0x00>;
				dma-names = "rx", "tx";
				status = "disabled";
				phandle = <0xdc>;
			};

			flexcan2: can@425b0000 {
				compatible = "fsl,imx95-flexcan";
				reg = <0x425b0000 0x10000>;
				interrupts = <0x00 0x26 0x04>;
				clocks = <0x11 0x77 0x11 0x78>;
				clock-names = "ipg", "per";
				assigned-clocks = <0x11 0x78>;
				assigned-clock-parents = <0x11 0x0a>;
				assigned-clock-rates = <0x2625a00>;
				fsl,clk-source = [00];
				status = "okay";
				pinctrl-names = "default";
				pinctrl-0 = <0x35>;
				xceiver-supply = <0x36>;
				phandle = <0xdd>;
			};

			flexcan3: can@42600000 {
				compatible = "fsl,imx95-flexcan";
				reg = <0x42600000 0x10000>;
				interrupts = <0x00 0x28 0x04>;
				clocks = <0x11 0x77 0x11 0x79>;
				clock-names = "ipg", "per";
				assigned-clocks = <0x11 0x79>;
				assigned-clock-parents = <0x11 0x0a>;
				assigned-clock-rates = <0x2625a00>;
				fsl,clk-source = [00];
				status = "disabled";
				phandle = <0xde>;
			};

			flexspi1: spi@425e0000 {
				compatible = "nxp,imx8mm-fspi";
				reg = <0x425e0000 0x10000 0x28000000 0x8000000>;
				reg-names = "fspi_base", "fspi_mmap";
				#address-cells = <0x01>;
				#size-cells = <0x00>;
				interrupts = <0x00 0x30 0x04>;
				clocks = <0x11 0x7e 0x11 0x7e>;
				clock-names = "fspi_en", "fspi";
				assigned-clocks = <0x11 0x7e>;
				assigned-clock-parents = <0x11 0x09>;
				assigned-clock-rates = <0xbebc200>;
				status = "disabled";
				phandle = <0xdf>;
			};

			sai3: sai@42650000 {
				compatible = "fsl,imx95-sai";
				reg = <0x42650000 0x10000>;
				interrupts = <0x00 0xaa 0x04>;
				clocks = <0x11 0x77 0x37 0x11 0x94 0x37 0x37>;
				clock-names = "bus", "mclk0", "mclk1", "mclk2", "mclk3";
				dmas = <0x28 0x3d 0x00 0x01 0x28 0x3c 0x00 0x00>;
				dma-names = "rx", "tx";
				status = "disabled";
				phandle = <0xe0>;
			};

			sai4: sai@42660000 {
				compatible = "fsl,imx95-sai";
				reg = <0x42660000 0x10000>;
				interrupts = <0x00 0xab 0x04>;
				clocks = <0x11 0x77 0x37 0x11 0x95 0x37 0x37>;
				clock-names = "bus", "mclk0", "mclk1", "mclk2", "mclk3";
				dmas = <0x28 0x44 0x00 0x01 0x28 0x43 0x00 0x00>;
				dma-names = "rx", "tx";
				status = "disabled";
				phandle = <0xe1>;
			};

			sai5: sai@42670000 {
				compatible = "fsl,imx95-sai";
				reg = <0x42670000 0x10000>;
				interrupts = <0x00 0xac 0x04>;
				clocks = <0x11 0x77 0x37 0x11 0x96 0x37 0x37>;
				clock-names = "bus", "mclk0", "mclk1", "mclk2", "mclk3";
				dmas = <0x28 0x46 0x00 0x01 0x28 0x45 0x00 0x00>;
				dma-names = "rx", "tx";
				status = "okay";
				assigned-clocks = <0x11 0x0e 0x11 0x10 0x11 0x0f 0x11 0x11 0x11 0x96>;
				assigned-clock-parents = <0x00 0x00 0x00 0x00 0x11 0x0f>;
				assigned-clock-rates = <0xea600000 0xd7550000 0x17700000 0x15888000 0xbb8000>;
				#sound-dai-cells = <0x00>;
				pinctrl-0 = <0x38>;
				pinctrl-names = "default";
				fsl,sai-mclk-direction-output;
				phandle = <0xa4>;
			};

			xcvr: xcvr@42680000 {
				compatible = "fsl,imx95-xcvr";
				reg = <0x42680000 0x800 0x42680800 0x400 0x42680c00 0x80 0x42680e00 0x80>;
				reg-names = "ram", "regs", "rxfifo", "txfifo";
				interrupts = <0x00 0xbd 0x04 0x00 0xbe 0x04>;
				clocks = <0x11 0x77 0x11 0x97 0x37 0x11 0x76>;
				clock-names = "ipg", "phy", "spba", "pll_ipg";
				dmas = <0x28 0x41 0x00 0x01 0x28 0x42 0x00 0x00>;
				dma-names = "rx", "tx";
				status = "disabled";
				phandle = <0xe2>;
			};

			flexio_i2c_master: flexio@425c0000 {
				compatible = "imx,flexio_i2c_master";
				reg = <0x425c0000 0x10000>;
				interrupts = <0x00 0x2e 0x04>;
				clocks = <0x11 0x77 0x11 0x77>;
				clock-names = "per", "ipg";
				assigned-clocks = <0x11 0x77>;
				assigned-clock-parents = <0x11 0x77>;
				assigned-clock-rates = <0x16e3600>;
				status = "disabled";
				phandle = <0xe3>;
			};

			lpuart7: serial@42690000 {
				compatible = "fsl,imx95-lpuart", "fsl,imx8ulp-lpuart", "fsl,imx7ulp-lpuart";
				reg = <0x42690000 0x1000>;
				interrupts = <0x00 0x44 0x04>;
				clocks = <0x11 0x92>;
				clock-names = "ipg";
				dmas = <0x28 0x58 0x00 0x01 0x28 0x57 0x00 0x00>;
				dma-names = "rx", "tx";
				status = "disabled";
				phandle = <0xe4>;
			};

			lpuart8: serial@426a0000 {
				compatible = "fsl,imx95-lpuart", "fsl,imx8ulp-lpuart", "fsl,imx7ulp-lpuart";
				reg = <0x426a0000 0x1000>;
				interrupts = <0x00 0x45 0x04>;
				clocks = <0x11 0x93>;
				clock-names = "ipg";
				dmas = <0x28 0x5a 0x00 0x01 0x28 0x59 0x00 0x00>;
				dma-names = "rx", "tx";
				status = "disabled";
				phandle = <0xe5>;
			};

			lpi2c5: i2c@426b0000 {
				compatible = "fsl,imx95-lpi2c", "fsl,imx7ulp-lpi2c";
				reg = <0x426b0000 0x10000>;
				interrupts = <0x00 0xb5 0x04>;
				clocks = <0x11 0x83 0x11 0x77>;
				clock-names = "per", "ipg";
				#address-cells = <0x01>;
				#size-cells = <0x00>;
				dmas = <0x28 0x47 0x00 0x00 0x28 0x48 0x00 0x01>;
				dma-names = "tx", "rx";
				status = "disabled";
				phandle = <0xe6>;
			};

			lpi2c6: i2c@426c0000 {
				compatible = "fsl,imx95-lpi2c", "fsl,imx7ulp-lpi2c";
				reg = <0x426c0000 0x10000>;
				interrupts = <0x00 0xb6 0x04>;
				clocks = <0x11 0x84 0x11 0x77>;
				clock-names = "per", "ipg";
				#address-cells = <0x01>;
				#size-cells = <0x00>;
				dmas = <0x28 0x49 0x00 0x00 0x28 0x4a 0x00 0x01>;
				dma-names = "tx", "rx";
				status = "disabled";
				phandle = <0xe7>;
			};

			lpi2c7: i2c@426d0000 {
				compatible = "fsl,imx95-lpi2c", "fsl,imx7ulp-lpi2c";
				reg = <0x426d0000 0x10000>;
				interrupts = <0x00 0xb7 0x04>;
				clocks = <0x11 0x85 0x11 0x77>;
				clock-names = "per", "ipg";
				#address-cells = <0x01>;
				#size-cells = <0x00>;
				dmas = <0x28 0x4b 0x00 0x00 0x28 0x4c 0x00 0x01>;
				dma-names = "tx", "rx";
				status = "disabled";
				phandle = <0xe8>;
			};

			lpi2c8: i2c@426e0000 {
				compatible = "fsl,imx95-lpi2c", "fsl,imx7ulp-lpi2c";
				reg = <0x426e0000 0x10000>;
				interrupts = <0x00 0xb8 0x04>;
				clocks = <0x11 0x86 0x11 0x77>;
				clock-names = "per", "ipg";
				#address-cells = <0x01>;
				#size-cells = <0x00>;
				dmas = <0x28 0x4d 0x00 0x00 0x28 0x4e 0x00 0x01>;
				dma-names = "tx", "rx";
				status = "disabled";
				phandle = <0xe9>;
			};

			lpspi5: spi@426f0000 {
				#address-cells = <0x01>;
				#size-cells = <0x00>;
				compatible = "fsl,imx95-spi", "fsl,imx7ulp-spi";
				reg = <0x426f0000 0x10000>;
				interrupts = <0x00 0xb1 0x04>;
				clocks = <0x11 0x89 0x11 0x77>;
				clock-names = "per", "ipg";
				dmas = <0x28 0x4f 0x00 0x00 0x28 0x50 0x00 0x01>;
				dma-names = "tx", "rx";
				status = "disabled";
				phandle = <0xea>;
			};

			lpspi6: spi@42700000 {
				#address-cells = <0x01>;
				#size-cells = <0x00>;
				compatible = "fsl,imx95-spi", "fsl,imx7ulp-spi";
				reg = <0x42700000 0x10000>;
				interrupts = <0x00 0xb2 0x04>;
				clocks = <0x11 0x8a 0x11 0x77>;
				clock-names = "per", "ipg";
				dmas = <0x28 0x51 0x00 0x00 0x28 0x52 0x00 0x01>;
				dma-names = "tx", "rx";
				status = "disabled";
				phandle = <0xeb>;
			};

			lpspi7: spi@42710000 {
				#address-cells = <0x01>;
				#size-cells = <0x00>;
				compatible = "fsl,imx95-spi", "fsl,imx7ulp-spi";
				reg = <0x42710000 0x10000>;
				interrupts = <0x00 0xb3 0x04>;
				clocks = <0x11 0x8b 0x11 0x77>;
				clock-names = "per", "ipg";
				dmas = <0x28 0x53 0x00 0x00 0x28 0x54 0x00 0x01>;
				dma-names = "tx", "rx";
				status = "disabled";
				phandle = <0xec>;
			};

			lpspi8: spi@42720000 {
				#address-cells = <0x01>;
				#size-cells = <0x00>;
				compatible = "fsl,imx95-spi", "fsl,imx7ulp-spi";
				reg = <0x42720000 0x10000>;
				interrupts = <0x00 0xb4 0x04>;
				clocks = <0x11 0x8c 0x11 0x77>;
				clock-names = "per", "ipg";
				dmas = <0x28 0x55 0x00 0x00 0x28 0x56 0x00 0x01>;
				dma-names = "tx", "rx";
				status = "disabled";
				phandle = <0xed>;
			};

			mu8: mailbox@42730000 {
				compatible = "fsl,imx95-mu";
				reg = <0x42730000 0x10000>;
				interrupts = <0x00 0xeb 0x04>;
				clocks = <0x11 0x77>;
				#mbox-cells = <0x02>;
				status = "disabled";
				phandle = <0xee>;
			};

			flexcan4: can@427c0000 {
				compatible = "fsl,imx95-flexcan";
				reg = <0x427c0000 0x10000>;
				interrupts = <0x00 0x2a 0x04>;
				clocks = <0x11 0x77 0x11 0x7a>;
				clock-names = "ipg", "per";
				assigned-clocks = <0x11 0x7a>;
				assigned-clock-parents = <0x11 0x0a>;
				assigned-clock-rates = <0x2625a00>;
				fsl,clk-source = [00];
				status = "disabled";
				phandle = <0xef>;
			};

			flexcan5: can@427d0000 {
				compatible = "fsl,imx95-flexcan";
				reg = <0x427d0000 0x10000>;
				interrupts = <0x00 0x2c 0x04>;
				clocks = <0x11 0x77 0x11 0x7b>;
				clock-names = "ipg", "per";
				assigned-clocks = <0x11 0x7b>;
				assigned-clock-parents = <0x11 0x0a>;
				assigned-clock-rates = <0x2625a00>;
				fsl,clk-source = [00];
				status = "okay";
				pinctrl-names = "default";
				pinctrl-0 = <0x39>;
				xceiver-supply = <0x36>;
				phandle = <0xf0>;
			};
		};

		aips3: bus@42800000 {
			compatible = "fsl,aips-bus", "simple-bus";
			reg = <0x00 0x42800000 0x00 0x800000>;
			#address-cells = <0x01>;
			#size-cells = <0x01>;
			ranges = <0x42800000 0x00 0x42800000 0x800000>;
			phandle = <0xf1>;

			usdhc1: mmc@42850000 {
				compatible = "fsl,imx95-usdhc", "fsl,imx8mm-usdhc";
				reg = <0x42850000 0x10000>;
				interrupts = <0x00 0x56 0x04>;
				clocks = <0x11 0x77 0x11 0xa2 0x11 0x9e>;
				clock-names = "ipg", "ahb", "per";
				assigned-clocks = <0x11 0x9e>;
				assigned-clock-parents = <0x11 0x09>;
				assigned-clock-rates = <0x17d78400>;
				bus-width = <0x08>;
				fsl,tuning-start-tap = <0x01>;
				fsl,tuning-step = <0x01>;
				iommus = <0x27 0x01>;
				status = "okay";
				pinctrl-names = "default", "state_100mhz", "state_200mhz", "sleep";
				pinctrl-0 = <0x3a>;
				pinctrl-1 = <0x3b>;
				pinctrl-2 = <0x3c>;
				pinctrl-3 = <0x3a>;
				non-removable;
				no-sdio;
				no-sd;
				phandle = <0xf2>;
			};

			usdhc2: mmc@42860000 {
				compatible = "fsl,imx95-usdhc", "fsl,imx8mm-usdhc";
				reg = <0x42860000 0x10000>;
				interrupts = <0x00 0x57 0x04>;
				clocks = <0x11 0x77 0x11 0xa2 0x11 0x9f>;
				clock-names = "ipg", "ahb", "per";
				assigned-clocks = <0x11 0x9f>;
				assigned-clock-parents = <0x11 0x09>;
				assigned-clock-rates = <0x17d78400>;
				bus-width = <0x04>;
				fsl,tuning-start-tap = <0x01>;
				fsl,tuning-step = <0x01>;
				iommus = <0x27 0x02>;
				status = "okay";
				pinctrl-names = "default", "state_100mhz", "state_200mhz", "sleep";
				pinctrl-0 = <0x3d 0x3e>;
				pinctrl-1 = <0x3f 0x3e>;
				pinctrl-2 = <0x40 0x3e>;
				pinctrl-3 = <0x3d 0x3e>;
				cd-gpios = <0x41 0x00 0x01>;
				fsl,cd-gpio-wakeup-disable;
				vmmc-supply = <0x42>;
				phandle = <0xf3>;
			};

			usdhc3: mmc@428b0000 {
				compatible = "fsl,imx95-usdhc", "fsl,imx8mm-usdhc";
				reg = <0x428b0000 0x10000>;
				interrupts = <0x00 0xbf 0x04>;
				clocks = <0x11 0x77 0x11 0xa2 0x11 0xa0>;
				clock-names = "ipg", "ahb", "per";
				assigned-clocks = <0x11 0xa0>;
				assigned-clock-parents = <0x11 0x09>;
				assigned-clock-rates = <0x17d78400>;
				bus-width = <0x04>;
				fsl,tuning-start-tap = <0x01>;
				fsl,tuning-step = <0x02>;
				iommus = <0x27 0x03>;
				status = "okay";
				pinctrl-names = "default", "state_100mhz", "state_200mhz", "sleep";
				pinctrl-0 = <0x43>;
				pinctrl-1 = <0x44>;
				pinctrl-2 = <0x45>;
				pinctrl-3 = <0x43>;
				mmc-pwrseq = <0x46>;
				vmmc-supply = <0x47>;
				keep-power-in-suspend;
				non-removable;
				wakeup-source;
				phandle = <0xf4>;
			};
		};

		gpio2: gpio@43810000 {
			compatible = "fsl,imx95-gpio", "fsl,imx8ulp-gpio";
			reg = <0x00 0x43810000 0x00 0x1000>;
			gpio-controller;
			#gpio-cells = <0x02>;
			interrupts = <0x00 0x31 0x04 0x00 0x32 0x04>;
			interrupt-controller;
			#interrupt-cells = <0x02>;
			clocks = <0x11 0x77 0x11 0x77>;
			clock-names = "gpio", "port";
			gpio-ranges = <0x48 0x00 0x04 0x20>;
			ngpios = <0x20>;
			phandle = <0x33>;
		};

		gpio3: gpio@43820000 {
			compatible = "fsl,imx95-gpio", "fsl,imx8ulp-gpio";
			reg = <0x00 0x43820000 0x00 0x1000>;
			gpio-controller;
			#gpio-cells = <0x02>;
			interrupts = <0x00 0x33 0x04 0x00 0x34 0x04>;
			interrupt-controller;
			#interrupt-cells = <0x02>;
			clocks = <0x11 0x77 0x11 0x77>;
			clock-names = "gpio", "port";
			gpio-ranges = <0x48 0x00 0x68 0x08 0x48 0x08 0x4a 0x12 0x48 0x1a 0x2a 0x02 0x48 0x1c 0x00 0x04>;
			ngpios = <0x20>;
			phandle = <0x41>;
		};

		gpio4: gpio@43840000 {
			compatible = "fsl,imx95-gpio", "fsl,imx8ulp-gpio";
			reg = <0x00 0x43840000 0x00 0x1000>;
			gpio-controller;
			#gpio-cells = <0x02>;
			interrupts = <0x00 0x35 0x04 0x00 0x36 0x04>;
			interrupt-controller;
			#interrupt-cells = <0x02>;
			clocks = <0x11 0x77 0x11 0x77>;
			clock-names = "gpio", "port";
			gpio-ranges = <0x48 0x00 0x2e 0x1c 0x48 0x1c 0x2c 0x02>;
			ngpios = <0x1e>;
			phandle = <0xf5>;
		};

		gpio5: gpio@43850000 {
			compatible = "fsl,imx95-gpio", "fsl,imx8ulp-gpio";
			reg = <0x00 0x43850000 0x00 0x1000>;
			gpio-controller;
			#gpio-cells = <0x02>;
			interrupts = <0x00 0x37 0x04 0x00 0x38 0x04>;
			interrupt-controller;
			#interrupt-cells = <0x02>;
			clocks = <0x11 0x77 0x11 0x77>;
			clock-names = "gpio", "port";
			gpio-ranges = <0x48 0x00 0x5c 0x0c 0x48 0x0c 0x24 0x06>;
			ngpios = <0x12>;
			phandle = <0x2a>;
		};

		aips1: bus@44000000 {
			compatible = "fsl,aips-bus", "simple-bus";
			reg = <0x00 0x44000000 0x00 0x800000>;
			ranges = <0x44000000 0x00 0x44000000 0x800000>;
			#address-cells = <0x01>;
			#size-cells = <0x01>;
			phandle = <0xf6>;

			edma1: dma-controller@44000000 {
				compatible = "fsl,imx93-edma3";
				reg = <0x44000000 0x200000>;
				#dma-cells = <0x03>;
				dma-channels = <0x1f>;
				interrupts = <0x00 0x60 0x04 0x00 0x61 0x04 0x00 0x62 0x04 0x00 0x63 0x04 0x00 0x64 0x04 0x00 0x65 0x04 0x00 0x66 0x04 0x00 0x67 0x04 0x00 0x68 0x04 0x00 0x69 0x04 0x00 0x6a 0x04 0x00 0x6b 0x04 0x00 0x6c 0x04 0x00 0x6d 0x04 0x00 0x6e 0x04 0x00 0x6f 0x04 0x00 0x70 0x04 0x00 0x71 0x04 0x00 0x72 0x04 0x00 0x73 0x04 0x00 0x74 0x04 0x00 0x75 0x04 0x00 0x76 0x04 0x00 0x77 0x04 0x00 0x78 0x04 0x00 0x79 0x04 0x00 0x7a 0x04 0x00 0x7b 0x04 0x00 0x7c 0x04 0x00 0x7d 0x04 0x00 0x7e 0x04 0x00 0x5f 0x04>;
				clocks = <0x11 0x2b>;
				clock-names = "dma";
				phandle = <0x4a>;
			};

			mu1: mailbox@44220000 {
				compatible = "fsl,imx95-mu";
				reg = <0x44220000 0x10000>;
				interrupts = <0x00 0xe0 0x04>;
				clocks = <0x11 0x2b>;
				#mbox-cells = <0x02>;
				status = "disabled";
				phandle = <0xf7>;
			};

			system_counter: timer@44290000 {
				compatible = "nxp,imx95-sysctr-timer";
				reg = <0x44290000 0x30000>;
				interrupts = <0x00 0x48 0x04>;
				clocks = <0x49>;
				clock-names = "per";
				nxp,no-divider;
				phandle = <0xf8>;
			};

			tpm1: pwm@44310000 {
				compatible = "fsl,imx7ulp-pwm";
				reg = <0x44310000 0x1000>;
				clocks = <0x11 0x2b>;
				#pwm-cells = <0x03>;
				status = "disabled";
				phandle = <0xf9>;
			};

			tpm2: pwm@44320000 {
				compatible = "fsl,imx7ulp-pwm";
				reg = <0x44320000 0x1000>;
				clocks = <0x11 0x3c>;
				#pwm-cells = <0x03>;
				status = "disabled";
				phandle = <0xfa>;
			};

			i3c1: i3c@44330000 {
				compatible = "nxp,imx95-i3c", "silvaco,i3c-master-v1";
				reg = <0x44330000 0x10000>;
				interrupts = <0x00 0x0c 0x04>;
				#address-cells = <0x03>;
				#size-cells = <0x00>;
				clocks = <0x11 0x2b 0x11 0x2e>;
				clock-names = "pclk", "fast_clk";
				status = "disabled";
				phandle = <0xfb>;
			};

			lpi2c1: i2c@44340000 {
				compatible = "fsl,imx95-lpi2c", "fsl,imx7ulp-lpi2c";
				reg = <0x44340000 0x10000>;
				interrupts = <0x00 0x0d 0x04>;
				clocks = <0x11 0x2f 0x11 0x2b>;
				clock-names = "per", "ipg";
				#address-cells = <0x01>;
				#size-cells = <0x00>;
				dmas = <0x4a 0x0c 0x00 0x00 0x4a 0x0d 0x00 0x01>;
				dma-names = "tx", "rx";
				status = "disabled";
				phandle = <0xfc>;
			};

			lpi2c2: i2c@44350000 {
				compatible = "fsl,imx95-lpi2c", "fsl,imx7ulp-lpi2c";
				reg = <0x44350000 0x10000>;
				interrupts = <0x00 0x0e 0x04>;
				clocks = <0x11 0x30 0x11 0x2b>;
				clock-names = "per", "ipg";
				#address-cells = <0x01>;
				#size-cells = <0x00>;
				dmas = <0x4a 0x0e 0x00 0x00 0x4a 0x0f 0x00 0x01>;
				dma-names = "tx", "rx";
				status = "okay";
				clock-frequency = <0x61a80>;
				pinctrl-names = "default";
				pinctrl-0 = <0x4b>;
				phandle = <0xfd>;

				pcal6524: gpio@22 {
					compatible = "nxp,pcal6524";
					pinctrl-names = "default";
					pinctrl-0 = <0x4c>;
					reg = <0x22>;
					gpio-controller;
					#gpio-cells = <0x02>;
					interrupt-controller;
					#interrupt-cells = <0x02>;
					interrupt-parent = <0x2a>;
					interrupts = <0x0e 0x08>;
					gpio-line-names = "ENET1 PHY reset", "ENET2 PHY reset", "SPI3/GPIO select", "UART3/GPIO select", "CAN2&5/GPIO select", "PWM/GPIO select", "Watch dog enable", "CAN1&2&5 silent or normal select", "Wifi reset", "Wifi power down and IO EXP reset", "Bluetooth reset", "Mkey Power Enable", "", "", "", "USB Power Enable", "MIPI-DSI panel touch reset", "MIPI-DSI and CSI reset", "MIPI-DSI panel backlight enable (Reserved)", "MIPI-CSI camera reset", "LVDS panel touch reset", "LVDS panel backlight enable", "LVDS panel backlight power enable", "LVDS to HDMI converter IT6263 reset";
					phandle = <0x2f>;

					lpspi-gpio-sel-hog {
						gpio-hog;
						gpios = <0x02 0x00>;
						output-low;
					};

					lpuart-gpio-sel-hog {
						gpio-hog;
						gpios = <0x03 0x00>;
						output-low;
					};

					can-gpio-sel-hog {
						gpio-hog;
						gpios = <0x04 0x00>;
						output-low;
					};

					pwm-gpio-sel-hog {
						gpio-hog;
						gpios = <0x05 0x00>;
						output-high;
					};
				};

				pcal6408_b: gpio@20 {
					compatible = "nxp,pcal9554b";
					reg = <0x20>;
					gpio-controller;
					#gpio-cells = <0x02>;
					vcc-supply = <0x47>;
					status = "okay";
					phandle = <0xfe>;

					iw610-buffer-enable-hog {
						gpio-hog;
						gpios = <0x00 0x00>;
						output-high;
					};
				};
			};

			lpspi1: spi@44360000 {
				#address-cells = <0x01>;
				#size-cells = <0x00>;
				compatible = "fsl,imx95-spi", "fsl,imx7ulp-spi";
				reg = <0x44360000 0x10000>;
				interrupts = <0x00 0x10 0x04>;
				clocks = <0x11 0x31 0x11 0x2b>;
				clock-names = "per", "ipg";
				dmas = <0x4a 0x10 0x00 0x01 0x4a 0x11 0x00 0x00>;
				dma-names = "tx", "rx";
				status = "disabled";
				phandle = <0xff>;
			};

			lpspi2: spi@44370000 {
				#address-cells = <0x01>;
				#size-cells = <0x00>;
				compatible = "fsl,imx95-spi", "fsl,imx7ulp-spi";
				reg = <0x44370000 0x10000>;
				interrupts = <0x00 0x11 0x04>;
				clocks = <0x11 0x32 0x11 0x2b>;
				clock-names = "per", "ipg";
				dmas = <0x4a 0x12 0x00 0x01 0x4a 0x13 0x00 0x00>;
				dma-names = "tx", "rx";
				status = "disabled";
				phandle = <0x100>;
			};

			lpuart1: serial@44380000 {
				compatible = "fsl,imx95-lpuart", "fsl,imx8ulp-lpuart", "fsl,imx7ulp-lpuart";
				reg = <0x44380000 0x1000>;
				interrupts = <0x00 0x13 0x04>;
				clocks = <0x11 0x34>;
				clock-names = "ipg";
				dmas = <0x4a 0x15 0x00 0x01 0x4a 0x14 0x00 0x00>;
				dma-names = "rx", "tx";
				status = "okay";
				pinctrl-names = "default";
				pinctrl-0 = <0x4d>;
				phandle = <0x101>;
			};

			lpuart2: serial@44390000 {
				compatible = "fsl,imx95-lpuart", "fsl,imx8ulp-lpuart", "fsl,imx7ulp-lpuart";
				reg = <0x44390000 0x1000>;
				interrupts = <0x00 0x14 0x04>;
				clocks = <0x11 0x35>;
				clock-names = "ipg";
				dmas = <0x4a 0x17 0x00 0x01 0x4a 0x16 0x00 0x00>;
				dma-names = "rx", "tx";
				status = "disabled";
				phandle = <0x102>;
			};

			flexcan1: can@443a0000 {
				compatible = "fsl,imx95-flexcan";
				reg = <0x443a0000 0x10000>;
				interrupts = <0x00 0x08 0x04>;
				clocks = <0x11 0x2b 0x11 0x2c>;
				clock-names = "ipg", "per";
				assigned-clocks = <0x11 0x2c>;
				assigned-clock-parents = <0x11 0x0a>;
				assigned-clock-rates = <0x2625a00>;
				fsl,clk-source = [00];
				status = "disabled";
				phandle = <0x103>;
			};

			sai1: sai@443b0000 {
				compatible = "fsl,imx95-sai";
				reg = <0x443b0000 0x10000>;
				interrupts = <0x00 0x22 0x04>;
				clocks = <0x11 0x2b 0x37 0x11 0x3a 0x37 0x37 0x11 0x0f 0x11 0x11>;
				clock-names = "bus", "mclk0", "mclk1", "mclk2", "mclk3", "pll8k", "pll11k";
				dmas = <0x4a 0x19 0x00 0x01 0x4a 0x18 0x00 0x00>;
				dma-names = "rx", "tx";
				status = "okay";
				#sound-dai-cells = <0x00>;
				assigned-clocks = <0x11 0x0e 0x11 0x10 0x11 0x0f 0x11 0x11 0x11 0x3a>;
				assigned-clock-parents = <0x00 0x00 0x00 0x00 0x11 0x0f>;
				assigned-clock-rates = <0xea600000 0xd7550000 0x17700000 0x15888000 0x1770000>;
				fsl,sai-mclk-direction-output;
				phandle = <0x104>;

				ports {
					#address-cells = <0x01>;
					#size-cells = <0x00>;

					sai1_port1: port@1 {
						reg = <0x01>;
						dai-format = "left_j";
						bitclock-master;
						frame-master;
						playback-only;
						mclk-fs = <0x200>;
						phandle = <0xa7>;

						sai1_endpoint1: endpoint {
							system-clock-direction-out;
							remote-endpoint = <0x4e>;
							phandle = <0x13>;
						};
					};
				};
			};

			micfil: micfil@44520000 {
				compatible = "fsl,imx95-micfil", "fsl,imx93-micfil";
				reg = <0x44520000 0x10000>;
				interrupts = <0x00 0xbc 0x04 0x00 0xbb 0x04 0x00 0xba 0x04 0x00 0xb9 0x04>;
				clocks = <0x11 0x2b 0x11 0x39 0x11 0x0f 0x11 0x11 0x37>;
				clock-names = "ipg_clk", "ipg_clk_app", "pll8k", "pll11k", "clkext3";
				dmas = <0x4a 0x06 0x00 0x05>;
				dma-names = "rx";
				status = "okay";
				#sound-dai-cells = <0x00>;
				pinctrl-names = "default";
				pinctrl-0 = <0x4f>;
				assigned-clocks = <0x11 0x0e 0x11 0x10 0x11 0x0f 0x11 0x11 0x11 0x39>;
				assigned-clock-parents = <0x00 0x00 0x00 0x00 0x11 0x0f>;
				assigned-clock-rates = <0xea600000 0xd7550000 0x17700000 0x15888000 0x2ee0000>;
				phandle = <0xa5>;
			};

			adc1: adc@44530000 {
				compatible = "nxp,imx93-adc";
				reg = <0x44530000 0x10000>;
				interrupts = <0x00 0xc7 0x04 0x00 0xc8 0x04 0x00 0xc9 0x04>;
				clocks = <0x11 0x29>;
				clock-names = "ipg";
				#io-channel-cells = <0x01>;
				status = "okay";
				vref-supply = <0x50>;
				phandle = <0x105>;
			};

			mu2: mailbox@445b0000 {
				compatible = "fsl,imx95-mu";
				reg = <0x445b0000 0x1000>;
				ranges;
				interrupts = <0x00 0xe2 0x04>;
				#address-cells = <0x01>;
				#size-cells = <0x01>;
				#mbox-cells = <0x02>;
				phandle = <0x14>;

				sram0: sram@445b1000 {
					compatible = "mmio-sram";
					reg = <0x445b1000 0x400>;
					ranges = <0x00 0x445b1000 0x400>;
					#address-cells = <0x01>;
					#size-cells = <0x01>;
					phandle = <0x106>;

					scmi_buf0: scmi-sram-section@0 {
						compatible = "arm,scmi-shmem";
						reg = <0x00 0x80>;
						phandle = <0x15>;
					};

					scmi_buf1: scmi-sram-section@80 {
						compatible = "arm,scmi-shmem";
						reg = <0x80 0x80>;
						phandle = <0x16>;
					};
				};
			};

			mu3: mailbox@445d0000 {
				compatible = "fsl,imx95-mu";
				reg = <0x445d0000 0x10000>;
				interrupts = <0x00 0xe4 0x04>;
				clocks = <0x11 0x2b>;
				#mbox-cells = <0x02>;
				status = "disabled";
				phandle = <0x107>;
			};

			mu4: mailbox@445f0000 {
				compatible = "fsl,imx95-mu";
				reg = <0x445f0000 0x10000>;
				interrupts = <0x00 0xe6 0x04>;
				clocks = <0x11 0x2b>;
				#mbox-cells = <0x02>;
				status = "disabled";
				phandle = <0x108>;
			};

			mu6: mailbox@44630000 {
				compatible = "fsl,imx95-mu";
				reg = <0x44630000 0x10000>;
				interrupts = <0x00 0xce 0x04>;
				clocks = <0x11 0x2b>;
				#mbox-cells = <0x02>;
				status = "disabled";
				phandle = <0x109>;
			};
		};

		v2x_mu4: mailbox@47300000 {
			compatible = "fsl,imx95-mu-v2x";
			reg = <0x00 0x47300000 0x00 0x10000>;
			interrupts = <0x00 0x1b 0x04>;
			#mbox-cells = <0x02>;
			phandle = <0x91>;
		};

		v2x_mu6: mailbox@47320000 {
			compatible = "fsl,imx95-mu-v2x";
			reg = <0x00 0x47320000 0x00 0x10000>;
			interrupts = <0x00 0xfe 0x04>;
			#mbox-cells = <0x02>;
			phandle = <0x92>;
		};

		v2x_mu7: mailbox@47330000 {
			compatible = "fsl,imx95-mu-v2x";
			reg = <0x00 0x47330000 0x00 0x10000>;
			interrupts = <0x00 0x1c 0x04>;
			#mbox-cells = <0x02>;
			phandle = <0x93>;
		};

		v2x_mu8: mailbox@47340000 {
			compatible = "fsl,imx95-mu-v2x";
			reg = <0x00 0x47340000 0x00 0x10000>;
			interrupts = <0x00 0xef 0x04>;
			#mbox-cells = <0x02>;
			phandle = <0x94>;
		};

		v2x_mu: mailbox@47350000 {
			compatible = "fsl,imx95-mu-v2x";
			reg = <0x00 0x47350000 0x00 0x10000>;
			interrupts = <0x00 0xff 0x04>;
			#mbox-cells = <0x02>;
			phandle = <0x90>;
		};

		gpio1: gpio@47400000 {
			compatible = "fsl,imx95-gpio", "fsl,imx8ulp-gpio";
			reg = <0x00 0x47400000 0x00 0x1000>;
			gpio-controller;
			#gpio-cells = <0x02>;
			interrupts = <0x00 0x0a 0x04 0x00 0x0b 0x04>;
			interrupt-controller;
			#interrupt-cells = <0x02>;
			clocks = <0x11 0x36 0x11 0x36>;
			clock-names = "gpio", "port";
			gpio-ranges = <0x48 0x00 0x70 0x10>;
			ngpios = <0x10>;
			status = "disabled";
			phandle = <0x10a>;
		};

		ocotp: efuse@47510000 {
			compatible = "fsl,imx95-ocotp", "syscon";
			reg = <0x00 0x47510000 0x00 0x10000>;
			#address-cells = <0x01>;
			#size-cells = <0x01>;
			phandle = <0x10b>;

			eth_mac0: mac-address@0 {
				reg = <0x514 0x06>;
				phandle = <0x82>;
			};

			eth_mac1: mac-address@1 {
				reg = <0x1514 0x06>;
				phandle = <0x85>;
			};

			eth_mac2: mac-address@2 {
				reg = <0x2514 0x06>;
				phandle = <0x88>;
			};
		};

		elemu0: mailbox@47520000 {
			compatible = "fsl,imx95-mu-ele";
			reg = <0x00 0x47520000 0x00 0x10000>;
			interrupts = <0x00 0x15 0x04>;
			#mbox-cells = <0x02>;
			status = "disabled";
			phandle = <0x10c>;
		};

		elemu1: mailbox@47530000 {
			compatible = "fsl,imx95-mu-ele";
			reg = <0x00 0x47530000 0x00 0x10000>;
			interrupts = <0x00 0x16 0x04>;
			#mbox-cells = <0x02>;
			status = "disabled";
			phandle = <0x10d>;
		};

		elemu2: mailbox@47540000 {
			compatible = "fsl,imx95-mu-ele";
			reg = <0x00 0x47540000 0x00 0x10000>;
			interrupts = <0x00 0x17 0x04>;
			#mbox-cells = <0x02>;
			status = "disabled";
			phandle = <0x10e>;
		};

		elemu3: mailbox@47550000 {
			compatible = "fsl,imx95-mu-ele";
			reg = <0x00 0x47550000 0x00 0x10000>;
			interrupts = <0x00 0x18 0x04>;
			#mbox-cells = <0x02>;
			phandle = <0x8e>;
		};

		elemu4: mailbox@47560000 {
			compatible = "fsl,imx95-mu-ele";
			reg = <0x00 0x47560000 0x00 0x10000>;
			interrupts = <0x00 0x19 0x04>;
			#mbox-cells = <0x02>;
			status = "disabled";
			phandle = <0x10f>;
		};

		elemu5: mailbox@47570000 {
			compatible = "fsl,imx95-mu-ele";
			reg = <0x00 0x47570000 0x00 0x10000>;
			interrupts = <0x00 0x1a 0x04>;
			#mbox-cells = <0x02>;
			status = "disabled";
			phandle = <0x110>;
		};

		aips4: bus@49000000 {
			compatible = "fsl,aips-bus", "simple-bus";
			reg = <0x00 0x49000000 0x00 0x800000>;
			ranges = <0x49000000 0x00 0x49000000 0x800000>;
			#address-cells = <0x01>;
			#size-cells = <0x01>;
			phandle = <0x111>;

			smmu: iommu@490d0000 {
				compatible = "arm,smmu-v3";
				reg = <0x490d0000 0x40000>;
				interrupts = <0x00 0x145 0x01 0x00 0x148 0x01 0x00 0x14e 0x01 0x00 0x146 0x01>;
				interrupt-names = "eventq", "gerror", "priq", "cmdq-sync";
				#iommu-cells = <0x01>;
				phandle = <0x27>;
			};

			pmu@490d2000 {
				compatible = "arm,smmu-v3-pmcg";
				reg = <0x490d2000 0x1000 0x490f2000 0x1000>;
				interrupts = <0x00 0x14d 0x01>;
			};

			pmu@49112000 {
				compatible = "arm,smmu-v3-pmcg";
				reg = <0x49112000 0x1000 0x49122000 0x1000>;
				interrupts = <0x00 0x143 0x01>;
			};

			pmu@49132000 {
				compatible = "arm,smmu-v3-pmcg";
				reg = <0x49132000 0x1000 0x49142000 0x1000>;
				interrupts = <0x00 0x143 0x01>;
			};

			pmu@49152000 {
				compatible = "arm,smmu-v3-pmcg";
				reg = <0x49152000 0x1000 0x49162000 0x1000>;
				interrupts = <0x00 0x143 0x01>;
			};

			pmu@49172000 {
				compatible = "arm,smmu-v3-pmcg";
				reg = <0x49172000 0x1000 0x49182000 0x1000>;
				interrupts = <0x00 0x143 0x01>;
			};

			pmu@49192000 {
				compatible = "arm,smmu-v3-pmcg";
				reg = <0x49192000 0x1000 0x491a2000 0x1000>;
				interrupts = <0x00 0x143 0x01>;
			};

			pmu@491b2000 {
				compatible = "arm,smmu-v3-pmcg";
				reg = <0x491b2000 0x1000 0x491c2000 0x1000>;
				interrupts = <0x00 0x143 0x01>;
			};

			pmu@491d2000 {
				compatible = "arm,smmu-v3-pmcg";
				reg = <0x491d2000 0x1000 0x491e2000 0x1000>;
				interrupts = <0x00 0x143 0x01>;
			};

			pmu@491f2000 {
				compatible = "arm,smmu-v3-pmcg";
				reg = <0x491f2000 0x1000 0x49202000 0x1000>;
				interrupts = <0x00 0x143 0x01>;
			};

			pmu@49212000 {
				compatible = "arm,smmu-v3-pmcg";
				reg = <0x49212000 0x1000 0x49222000 0x1000>;
				interrupts = <0x00 0x143 0x01>;
			};

			pmu@49232000 {
				compatible = "arm,smmu-v3-pmcg";
				reg = <0x49232000 0x1000 0x49242000 0x1000>;
				interrupts = <0x00 0x143 0x01>;
			};

			pmu@49252000 {
				compatible = "arm,smmu-v3-pmcg";
				reg = <0x49252000 0x1000 0x49262000 0x1000>;
				interrupts = <0x00 0x143 0x01>;
			};
		};

		cameramix_csr: syscon@4ac10000 {
			compatible = "nxp,imx95-camera-csr", "syscon";
			#address-cells = <0x01>;
			#size-cells = <0x01>;
			reg = <0x00 0x4ac10000 0x00 0x10000>;
			#clock-cells = <0x01>;
			clocks = <0x11 0x3e>;
			power-domains = <0x51 0x03>;
			phandle = <0x52>;

			csi_pixel_formatter_0: formatter@20 {
				compatible = "fsl,imx95-csi-formatter";
				reg = <0x20 0x100>;
				clocks = <0x52 0x00>;
				power-domains = <0x51 0x03>;
				nxp,neoisp = <0x53>;
				status = "disabled";
				phandle = <0x112>;

				ports {
					#address-cells = <0x01>;
					#size-cells = <0x00>;

					port@0 {
						reg = <0x00>;
					};

					port@1 {
						reg = <0x01>;
					};
				};
			};

			csi_pixel_formatter_1: formatter@120 {
				compatible = "fsl,imx95-csi-formatter";
				reg = <0x120 0x100>;
				clocks = <0x52 0x01>;
				power-domains = <0x51 0x03>;
				nxp,neoisp = <0x53>;
				status = "disabled";
				phandle = <0x113>;

				ports {
					#address-cells = <0x01>;
					#size-cells = <0x00>;

					port@0 {
						reg = <0x00>;
					};

					port@1 {
						reg = <0x01>;
					};
				};
			};
		};

		cameramix_mu1: mailbox@4ac60000 {
			compatible = "fsl,imx95-mu-isp";
			reg = <0x00 0x4ac60000 0x00 0x10000>;
			interrupts = <0x00 0xdc 0x04>;
			clocks = <0x11 0x3e>;
			power-domains = <0x51 0x03>;
			status = "disabled";
			phandle = <0x114>;
		};

		cameramix_mu2: mailbox@4ac70000 {
			compatible = "fsl,imx95-mu-isp";
			reg = <0x00 0x4ac70000 0x00 0x10000>;
			interrupts = <0x00 0x150 0x04>;
			clocks = <0x11 0x3e>;
			power-domains = <0x51 0x03>;
			status = "disabled";
			phandle = <0x115>;
		};

		cameramix_mu3: mailbox@4ac80000 {
			compatible = "fsl,imx95-mu-isp";
			reg = <0x00 0x4ac80000 0x00 0x10000>;
			interrupts = <0x00 0x151 0x04>;
			clocks = <0x11 0x3e>;
			power-domains = <0x51 0x03>;
			status = "disabled";
			phandle = <0x116>;
		};

		cameramix_mu4: mailbox@4ac90000 {
			compatible = "fsl,imx95-mu-isp";
			reg = <0x00 0x4ac90000 0x00 0x10000>;
			interrupts = <0x00 0x152 0x04>;
			clocks = <0x11 0x3e>;
			power-domains = <0x51 0x03>;
			status = "disabled";
			phandle = <0x117>;
		};

		cameramix_mu5: mailbox@4aca0000 {
			compatible = "fsl,imx95-mu-isp";
			reg = <0x00 0x4aca0000 0x00 0x10000>;
			interrupts = <0x00 0x153 0x04>;
			clocks = <0x11 0x3e>;
			power-domains = <0x51 0x03>;
			status = "disabled";
			phandle = <0x118>;
		};

		cameramix_mu6: mailbox@4acb0000 {
			compatible = "fsl,imx95-mu-isp";
			reg = <0x00 0x4acb0000 0x00 0x10000>;
			interrupts = <0x00 0x154 0x04>;
			clocks = <0x11 0x3e>;
			power-domains = <0x51 0x03>;
			status = "disabled";
			phandle = <0x119>;
		};

		cameramix_mu7: mailbox@4acc0000 {
			compatible = "fsl,imx95-mu-isp";
			reg = <0x00 0x4acc0000 0x00 0x10000>;
			interrupts = <0x00 0x155 0x04>;
			clocks = <0x11 0x3e>;
			power-domains = <0x51 0x03>;
			status = "disabled";
			phandle = <0x11a>;
		};

		cameramix_mu8: mailbox@4acd0000 {
			compatible = "fsl,imx95-mu-isp";
			reg = <0x00 0x4acd0000 0x00 0x10000>;
			interrupts = <0x00 0x156 0x04>;
			clocks = <0x11 0x3e>;
			power-domains = <0x51 0x03>;
			status = "disabled";
			phandle = <0x11b>;
		};

		cameramix_mu9: mailbox@4ace0000 {
			compatible = "fsl,imx95-mu-isp";
			reg = <0x00 0x4ace0000 0x00 0x10000>;
			interrupts = <0x00 0x157 0x04>;
			clocks = <0x11 0x3e>;
			power-domains = <0x51 0x03>;
			status = "disabled";
			phandle = <0x11c>;
		};

		ocram_c_config: syscon@4add0000 {
			compatible = "fsl,imx95-ocram-config", "syscon";
			#address-cells = <0x01>;
			#size-cells = <0x01>;
			reg = <0x00 0x4add0000 0x00 0x10000>;
			clocks = <0x11 0x3e>;
			power-domains = <0x51 0x03>;
			interrupt-parent = <0x01>;
			interrupts = <0x00 0xfb 0x04 0x00 0xfc 0x04 0x00 0xfd 0x04>;
			phandle = <0x54>;
		};

		ocram_c: ocram@4af80000 {
			reg = <0x00 0x4af80000 0x00 0x18000>;
			no-map;
			phandle = <0x55>;
		};

		isp_fw_core: remoteproc {
			compatible = "nxp,imx95-isp-rproc";
			nxp,blk-ctrl = <0x52>;
			nxp,ocram-cfg = <0x54>;
			nxp,isp-firmware = "imx9xm0p_isp_fw.bin";
			power-domains = <0x51 0x03>;
			status = "disabled";
			phandle = <0x11d>;

			mba {
				memory-region = <0x55>;
				ocram-map = <0x00 0x14000>;
			};
		};

		mipi_dsi: dsi@4acf0000 {
			compatible = "nxp,imx95-mipi-dsi";
			reg = <0x00 0x4acf0000 0x00 0x10000>;
			interrupt-parent = <0x56>;
			interrupts = <0x30>;
			clocks = <0x11 0x42 0x11 0x43 0x11 0x44 0x11 0x3e 0x11 0x50>;
			clock-names = "cfg", "bypass", "ref", "pclk", "pix";
			assigned-clocks = <0x11 0x42 0x11 0x43 0x11 0x44>;
			assigned-clock-parents = <0x11 0x02 0x11 0x13 0x11 0x02>;
			mux-controls = <0x57 0x00>;
			power-domains = <0x51 0x03>;
			nxp,disp-master-csr = <0x58>;
			nxp,disp-stream-csr = <0x59>;
			nxp,mipi-combo-phy-csr = <0x5a>;
			status = "disabled";
			phandle = <0x11e>;

			ports {
				#address-cells = <0x01>;
				#size-cells = <0x00>;

				port@0 {
					#address-cells = <0x01>;
					#size-cells = <0x00>;
					reg = <0x00>;

					mipi_dsi_to_display_pixel_link0: endpoint@0 {
						reg = <0x00>;
						remote-endpoint = <0x5b>;
						phandle = <0x64>;
					};

					mipi_dsi_to_display_pixel_link1: endpoint@1 {
						reg = <0x01>;
						remote-endpoint = <0x5c>;
						phandle = <0x66>;
					};
				};

				port@1 {
					reg = <0x01>;
				};
			};
		};

		display_stream_csr: syscon@4ad00000 {
			compatible = "nxp,imx95-display-stream-csr", "syscon", "simple-mfd";
			reg = <0x00 0x4ad00000 0x00 0x10000>;
			clocks = <0x11 0x3e>;
			phandle = <0x59>;
		};

		display_master_csr: syscon@4ad10000 {
			compatible = "nxp,imx95-display-master-csr", "syscon";
			reg = <0x00 0x4ad10000 0x00 0x10000>;
			#clock-cells = <0x01>;
			clocks = <0x11 0x3e>;
			power-domains = <0x51 0x03>;
			phandle = <0x58>;

			mux: mux-controller {
				compatible = "mmio-mux";
				#mux-control-cells = <0x01>;
				mux-reg-masks = <0x04 0x01>;
				idle-states = <0x00>;
				phandle = <0x57>;
			};
		};

		mipi_dsi_intf: syscon@4acf0000 {
			compatible = "syscon", "simple-mfd";
			reg = <0x00 0x4acf0000 0x00 0x10000>;
			clocks = <0x11 0x3e>;
			status = "disabled";
			phandle = <0x5f>;
		};

		combo_phy_csr: syscon@4ad20000 {
			compatible = "syscon", "simple-mfd";
			reg = <0x00 0x4ad20000 0x00 0x114>;
			#address-cells = <0x01>;
			#size-cells = <0x01>;
			clocks = <0x11 0x3e>;
			phandle = <0x11f>;

			dphy_rx: dphy-rx@0 {
				compatible = "fsl,imx95-dphy-rx";
				reg = <0x00 0x10>;
				clocks = <0x11 0x42>;
				clock-names = "phy_cfg";
				assigned-clocks = <0x11 0x42>;
				assigned-clock-parents = <0x11 0x02>;
				assigned-clock-rates = <0x16e3600>;
				#phy-cells = <0x00>;
				fsl,csis = <0x5d>;
				power-domains = <0x51 0x03>;
				status = "disabled";
				phandle = <0x60>;
			};

			combo_rx: combo-rx@100 {
				compatible = "fsl,imx95-combo-rx";
				reg = <0x100 0x10>;
				clocks = <0x11 0x42>;
				clock-names = "phy_cfg";
				assigned-clocks = <0x11 0x42>;
				assigned-clock-parents = <0x11 0x02>;
				assigned-clock-rates = <0x16e3600>;
				#phy-cells = <0x00>;
				fsl,csis = <0x5e>;
				fsl,dsi = <0x5f>;
				power-domains = <0x51 0x03>;
				status = "disabled";
				phandle = <0x61>;
			};
		};

		mipi_tx_phy_csr: syscon@4ad20100 {
			compatible = "fsl,imx95-mipi-tx-phy-csr", "syscon";
			reg = <0x00 0x4ad20100 0x00 0x14>;
			clocks = <0x11 0x3e>;
			phandle = <0x5a>;
		};

		mipi_csi0: csi@4ad30000 {
			compatible = "snps,dw-mipi-csi2", "syscon";
			reg = <0x00 0x4ad30000 0x00 0x10000>;
			interrupts = <0x00 0x176 0x04>;
			clocks = <0x11 0x3e>;
			clock-names = "per";
			phys = <0x60>;
			phy-names = "dphy-rx";
			power-domains = <0x51 0x03>;
			status = "disabled";
			phandle = <0x5d>;

			ports {
				#address-cells = <0x01>;
				#size-cells = <0x00>;

				port@0 {
					reg = <0x00>;
				};

				port@1 {
					reg = <0x01>;
				};
			};
		};

		mipi_csi1: csi@4ad40000 {
			compatible = "snps,dw-mipi-csi2", "syscon";
			reg = <0x00 0x4ad40000 0x00 0x10000>;
			interrupts = <0x00 0x177 0x04>;
			clocks = <0x11 0x3e>;
			clock-names = "per";
			phys = <0x61>;
			phy-names = "dphy-rx";
			power-domains = <0x51 0x03>;
			status = "disabled";
			phandle = <0x5e>;

			ports {
				#address-cells = <0x01>;
				#size-cells = <0x00>;

				port@0 {
					reg = <0x00>;
				};

				port@1 {
					reg = <0x01>;
				};
			};
		};

		isi: isi@4ad50000 {
			compatible = "fsl,imx95-isi";
			reg = <0x00 0x4ad50000 0x00 0x80000>;
			interrupts = <0x00 0xdd 0x04 0x00 0x158 0x04 0x00 0x159 0x04 0x00 0x15a 0x04 0x00 0x15b 0x04 0x00 0x15c 0x04 0x00 0x15d 0x04 0x00 0x15e 0x04>;
			clocks = <0x11 0x41>;
			clock-names = "axi";
			fsl,blk-ctrl = <0x52>;
			power-domains = <0x51 0x03>;
			status = "disabled";
			phandle = <0x120>;

			ports {
				#address-cells = <0x01>;
				#size-cells = <0x00>;

				port@0 {
					reg = <0x00>;
				};

				port@1 {
					reg = <0x01>;
				};

				port@2 {
					reg = <0x02>;
				};

				port@3 {
					reg = <0x03>;
				};
			};
		};

		neoisp0: isp@4ae00000 {
			compatible = "nxp,imx95-neoisp";
			reg = <0x00 0x4ae00000 0x00 0x8000 0x00 0x4afe0000 0x00 0x10000>;
			reg-names = "registers", "stats";
			interrupts = <0x00 0xde 0x04>;
			clocks = <0x52 0x02 0x52 0x03 0x52 0x04>;
			clock-names = "camblk_isp_axi", "camblk_isp_pixel", "camblk_isp";
			power-domains = <0x51 0x03>;
			nxp,blk-ctrl = <0x52>;
			status = "okay";
			phandle = <0x53>;
		};

		dispmix_csr: syscon@4b010000 {
			compatible = "nxp,imx95-display-csr", "syscon";
			#address-cells = <0x01>;
			#size-cells = <0x01>;
			reg = <0x00 0x4b010000 0x00 0x10000>;
			#clock-cells = <0x01>;
			clocks = <0x11 0x4b>;
			power-domains = <0x51 0x0d>;
			assigned-clocks = <0x11 0x4c 0x11 0x4e 0x11 0x4b>;
			assigned-clock-parents = <0x11 0x09 0x11 0x09 0x11 0x0a>;
			assigned-clock-rates = <0x17d78400 0x17d78400 0x7f28155>;
			phandle = <0x6e>;

			display_pixel_link: bridge@8 {
				compatible = "nxp,imx95-dc-pixel-link";
				reg = <0x08 0x04>;
				status = "okay";
				phandle = <0x121>;

				ports {
					#address-cells = <0x01>;
					#size-cells = <0x00>;

					port@0 {
						reg = <0x00>;

						display_pixel_link0_to_pixel_interleaver_disp0: endpoint {
							remote-endpoint = <0x62>;
							phandle = <0x70>;
						};
					};

					port@1 {
						reg = <0x01>;

						display_pixel_link1_to_pixel_interleaver_disp1: endpoint {
							remote-endpoint = <0x63>;
							phandle = <0x72>;
						};
					};

					port@2 {
						#address-cells = <0x01>;
						#size-cells = <0x00>;
						reg = <0x02>;

						display_pixel_link0_to_mipi_dsi: endpoint@0 {
							reg = <0x00>;
							remote-endpoint = <0x64>;
							phandle = <0x5b>;
						};

						display_pixel_link0_to_ldb_ch0: endpoint@1 {
							reg = <0x01>;
							remote-endpoint = <0x65>;
							phandle = <0x6a>;
						};
					};

					port@3 {
						#address-cells = <0x01>;
						#size-cells = <0x00>;
						reg = <0x03>;

						display_pixel_link1_to_mipi_dsi: endpoint@0 {
							reg = <0x00>;
							remote-endpoint = <0x66>;
							phandle = <0x5c>;
						};

						display_pixel_link1_to_ldb_ch1: endpoint@1 {
							reg = <0x01>;
							remote-endpoint = <0x67>;
							phandle = <0x6c>;
						};
					};
				};
			};
		};

		displaymix_irqsteer: interrupt-controller@4b0b0000 {
			compatible = "fsl,imx-irqsteer";
			reg = <0x00 0x4b0b0000 0x00 0x1000>;
			interrupts = <0x00 0xd6 0x04 0x00 0xd7 0x04 0x00 0xd8 0x04 0x00 0xd9 0x04 0x00 0xda 0x04 0x00 0x12f 0x04 0x00 0x12f 0x04 0x00 0xdb 0x04>;
			power-domains = <0x51 0x0d>;
			clocks = <0x11 0x4b>;
			clock-names = "ipg";
			fsl,channel = <0x00>;
			fsl,num-irqs = <0x200>;
			interrupt-controller;
			#interrupt-cells = <0x01>;
			status = "okay";
			phandle = <0x56>;
		};

		lvds_csr: syscon@4b0c0000 {
			compatible = "nxp,imx95-lvds-csr", "syscon";
			#address-cells = <0x01>;
			#size-cells = <0x01>;
			reg = <0x00 0x4b0c0000 0x00 0x10000>;
			#clock-cells = <0x01>;
			clocks = <0x11 0x4b>;
			power-domains = <0x51 0x0d>;
			phandle = <0x68>;

			ldb: ldb@4 {
				compatible = "fsl,imx95-ldb";
				#address-cells = <0x01>;
				#size-cells = <0x00>;
				reg = <0x04 0x04>;
				clocks = <0x68 0x03 0x68 0x04 0x68 0x01 0x68 0x02 0x11 0x26>;
				clock-names = "ldb_di0", "ldb_di1", "ldb_ch0", "ldb_ch1", "ldb_pll";
				status = "okay";
				phandle = <0x122>;

				channel@0 {
					#address-cells = <0x01>;
					#size-cells = <0x00>;
					reg = <0x00>;
					phys = <0x69>;
					phy-names = "lvds_phy";
					status = "disabled";

					port@0 {
						reg = <0x00>;

						ldb_ch0_to_display_pixel_link0: endpoint {
							remote-endpoint = <0x6a>;
							phandle = <0x65>;
						};
					};

					port@1 {
						reg = <0x01>;
					};
				};

				channel@1 {
					#address-cells = <0x01>;
					#size-cells = <0x00>;
					reg = <0x01>;
					phys = <0x6b>;
					phy-names = "lvds_phy";
					status = "okay";

					port@0 {
						reg = <0x00>;

						ldb_ch1_to_display_pixel_link1: endpoint {
							remote-endpoint = <0x6c>;
							phandle = <0x67>;
						};
					};

					port@1 {
						reg = <0x01>;

						lvds1_out: endpoint {
							remote-endpoint = <0x6d>;
							phandle = <0x30>;
						};
					};
				};
			};

			ldb0_phy: phy@8 {
				compatible = "fsl,imx95-lvds0-phy";
				#address-cells = <0x01>;
				#size-cells = <0x00>;
				reg = <0x08 0x04>;
				gpr = <0x68>;
				clocks = <0x11 0x4b>;
				clock-names = "apb";
				power-domains = <0x51 0x0d>;
				status = "disabled";
				phandle = <0x123>;

				ldb0_phy1: port@0 {
					reg = <0x00>;
					#phy-cells = <0x00>;
					phandle = <0x69>;
				};
			};

			ldb1_phy: phy@c {
				compatible = "fsl,imx95-lvds1-phy";
				#address-cells = <0x01>;
				#size-cells = <0x00>;
				reg = <0x0c 0x04>;
				gpr = <0x68>;
				clocks = <0x11 0x4b>;
				clock-names = "apb";
				power-domains = <0x51 0x0d>;
				status = "okay";
				phandle = <0x124>;

				ldb1_phy1: port@0 {
					reg = <0x00>;
					#phy-cells = <0x00>;
					phandle = <0x6b>;
				};
			};
		};

		pixel_interleaver: bridge@4b0d0000 {
			compatible = "nxp,imx95-pixel-interleaver";
			#address-cells = <0x01>;
			#size-cells = <0x00>;
			reg = <0x00 0x4b0d0000 0x00 0x20000>;
			interrupt-parent = <0x56>;
			interrupts = <0x3e>;
			clocks = <0x11 0x4b>;
			nxp,blk-ctrl = <0x6e>;
			status = "okay";
			phandle = <0x125>;

			channel@0 {
				#address-cells = <0x01>;
				#size-cells = <0x00>;
				reg = <0x00>;
				status = "disabled";

				port@0 {
					reg = <0x00>;

					pixel_interleaver_disp0_to_dpu_disp0: endpoint {
						remote-endpoint = <0x6f>;
						phandle = <0x74>;
					};
				};

				port@1 {
					reg = <0x01>;

					pixel_interleaver_disp0_to_display_pixel_link0: endpoint {
						remote-endpoint = <0x70>;
						phandle = <0x62>;
					};
				};
			};

			channel@1 {
				#address-cells = <0x01>;
				#size-cells = <0x00>;
				reg = <0x01>;
				status = "okay";

				port@0 {
					reg = <0x00>;

					pixel_interleaver_disp1_to_dpu_disp1: endpoint {
						remote-endpoint = <0x71>;
						phandle = <0x75>;
					};
				};

				port@1 {
					reg = <0x01>;

					pixel_interleaver_disp1_to_display_pixel_link1: endpoint {
						remote-endpoint = <0x72>;
						phandle = <0x63>;
					};
				};
			};
		};

		dpu: display-controller@4b400000 {
			compatible = "nxp,imx95-dpu";
			reg = <0x00 0x4b400000 0x00 0x400000>;
			interrupt-parent = <0x56>;
			interrupts = <0x1c0 0x1c1 0x1c2 0x40 0x41 0x42 0x43 0x44 0x45 0xc0 0xc1 0xc2 0xc3 0xc4 0xc5 0x46 0x47 0x48 0x49 0x4a 0x4b 0x4c 0x4d 0x4e 0x4f 0x50 0x51 0x52 0x53 0x54 0x55 0x56 0x57 0x58 0x59 0x5a 0x5b 0x5c 0xc6 0xc7 0xc8 0xc9 0xca 0xcb 0xcc 0xcd 0xce 0xcf 0xd0 0xd1 0xd2 0xd3 0xd4 0x1c3 0x01 0x02 0x03 0x04 0x5d 0x5e 0x5f 0x60 0x61 0x62 0x63 0x64 0x65 0x66 0x67 0x68 0x69 0x6a 0xd5 0xd6 0xd7 0xd8 0xd9 0xda 0xdb 0xdc 0xdd 0xde 0xdf 0xe0 0xe1 0xe2>;
			interrupt-names = "store9_shdload", "store9_framecomplete", "store9_seqcomplete", "extdst0_shdload", "extdst0_framecomplete", "extdst0_seqcomplete", "extdst4_shdload", "extdst4_framecomplete", "extdst4_seqcomplete", "extdst1_shdload", "extdst1_framecomplete", "extdst1_seqcomplete", "extdst5_shdload", "extdst5_framecomplete", "extdst5_seqcomplete", "domainblend0_shdload", "domainblend0_framecomplete", "domainblend0_seqcomplete", "disengcfg_shdload0", "disengcfg_framecomplete0", "disengcfg_seqcomplete0", "framegen0_int0", "framegen0_int1", "framegen0_int2", "framegen0_int3", "sig0_shdload", "sig0_valid", "sig0_error", "sig0_cluster_error", "sig0_cluster_match", "sig2_shdload", "sig2_valid", "sig2_error", "sig2_cluster_error", "sig2_cluster_match", "idhash0_shdload", "idhash0_valid", "idhash0_window_error", "domainblend1_shdload", "domainblend1_framecomplete", "domainblend1_seqcomplete", "disengcfg_shdload1", "disengcfg_framecomplete1", "disengcfg_seqcomplete1", "framegen1_int0", "framegen1_int1", "framegen1_int2", "framegen1_int3", "sig1_shdload", "sig1_valid", "sig1_error", "sig1_cluster_error", "sig1_cluster_match", "cmdseq_error", "comctrl_sw0", "comctrl_sw1", "comctrl_sw2", "comctrl_sw3", "framegen0_primsync_on", "framegen0_primsync_off", "framegen0_overflow0_on", "framegen0_overflow0_off", "framegen0_underrun0_on", "framegen0_underrun0_off", "framegen0_threshold0_rise", "framegen0_threshold0_fail", "framegen0_overflow1_on", "framegen0_overflow1_off", "framegen0_underrun1_on", "framegen0_underrun1_off", "framegen0_threshold1_rise", "framegen0_threshold1_fail", "framegen1_primsync_on", "framegen1_primsync_off", "framegen1_overflow0_on", "framegen1_overflow0_off", "framegen1_underrun0_on", "framegen1_underrun0_off", "framegen1_threshold0_rise", "framegen1_threshold0_fail", "framegen1_overflow1_on", "framegen1_overflow1_off", "framegen1_underrun1_on", "framegen1_underrun1_off", "framegen1_threshold1_rise", "framegen1_threshold1_fail";
			clocks = <0x11 0x50 0x11 0x4b 0x11 0x4c 0x11 0x4e 0x73 0x11 0x25>;
			clock-names = "pix", "apb", "axi", "ocram", "ldb", "ldb_vco";
			power-domains = <0x51 0x0d>;
			nxp,blk-ctrl = <0x6e>;
			status = "okay";
			phandle = <0x126>;

			ports {
				#address-cells = <0x01>;
				#size-cells = <0x00>;

				port@0 {
					reg = <0x00>;

					dpu_disp0_to_pixel_interleaver_disp0: endpoint {
						remote-endpoint = <0x74>;
						phandle = <0x6f>;
					};
				};

				port@1 {
					reg = <0x01>;

					dpu_disp1_to_pixel_interleaver_disp1: endpoint {
						remote-endpoint = <0x75>;
						phandle = <0x71>;
					};
				};
			};
		};

		usb3: usb@4c010010 {
			compatible = "fsl,imx95-dwc3", "fsl,imx8mp-dwc3";
			reg = <0x00 0x4c010010 0x00 0x04 0x00 0x4c1f0000 0x00 0x20>;
			clocks = <0x11 0x57 0x11 0x01>;
			clock-names = "hsio", "suspend";
			interrupts = <0x00 0xad 0x04>;
			#address-cells = <0x02>;
			#size-cells = <0x02>;
			ranges;
			power-domains = <0x51 0x0f>;
			dma-ranges = <0x00 0x00 0x00 0x00 0x10 0x00>;
			status = "okay";
			phandle = <0x127>;

			usb3_dwc3: usb@4c100000 {
				compatible = "snps,dwc3";
				reg = <0x00 0x4c100000 0x00 0x10000>;
				clocks = <0x11 0x57 0x11 0x02 0x11 0x01>;
				clock-names = "bus_early", "ref", "suspend";
				interrupts = <0x00 0xaf 0x04>;
				phys = <0x76 0x76>;
				phy-names = "usb2-phy", "usb3-phy";
				snps,gfladj-refclk-lpm-sel-quirk;
				snps,parkmode-disable-ss-quirk;
				iommus = <0x27 0x0e>;
				dr_mode = "otg";
				hnp-disable;
				srp-disable;
				adp-disable;
				usb-role-switch;
				role-switch-default-mode = "peripheral";
				snps,dis-u1-entry-quirk;
				snps,dis-u2-entry-quirk;
				status = "okay";
				phandle = <0x128>;

				port {

					usb3_data_hs: endpoint {
						remote-endpoint = <0x77>;
						phandle = <0x2c>;
					};
				};
			};
		};

		hsio_blk_ctl: syscon@4c0100c0 {
			compatible = "nxp,imx95-hsio-blk-ctl", "syscon";
			reg = <0x00 0x4c0100c0 0x00 0x01>;
			#clock-cells = <0x01>;
			clocks = <0x78>;
			power-domains = <0x51 0x0f>;
			phandle = <0x7d>;
		};

		usb3_phy: phy@4c1f0040 {
			compatible = "fsl,imx95-usb-phy", "fsl,imx8mp-usb-phy";
			reg = <0x00 0x4c1f0040 0x00 0x40 0x00 0x4c1fc000 0x00 0x100>;
			clocks = <0x11 0x57>;
			clock-names = "phy";
			#phy-cells = <0x00>;
			power-domains = <0x51 0x0f>;
			status = "okay";
			orientation-switch;
			fsl,phy-pcs-tx-deemph-3p5db-attenuation-db = <0x11>;
			fsl,phy-pcs-tx-swing-full-percent = <0x64>;
			fsl,phy-tx-preemp-amp-tune-microamp = <0x258>;
			fsl,phy-tx-vboost-level-microvolt = <0x484>;
			phandle = <0x76>;

			port {

				usb3_data_ss: endpoint {
					remote-endpoint = <0x79>;
					phandle = <0x2d>;
				};
			};
		};

		usb2: usb@4c200000 {
			compatible = "fsl,imx95-usb", "fsl,imx7d-usb", "fsl,imx27-usb";
			reg = <0x00 0x4c200000 0x00 0x200>;
			interrupts = <0x00 0xb0 0x04 0x00 0xae 0x04>;
			clocks = <0x11 0x57 0x11 0x01>;
			clock-names = "usb_ctrl_root", "usb_wakeup";
			iommus = <0x27 0x0f>;
			phys = <0x7a>;
			power-domains = <0x51 0x0f>;
			fsl,usbmisc = <0x7b 0x00>;
			status = "okay";
			dr_mode = "host";
			vbus-supply = <0x7c>;
			disable-over-current;
			phandle = <0x129>;
		};

		usbmisc: usbmisc@4c200200 {
			compatible = "fsl,imx95-usbmisc", "fsl,imx7d-usbmisc", "fsl,imx6q-usbmisc";
			reg = <0x00 0x4c200200 0x00 0x200 0x00 0x4c010014 0x00 0x04>;
			#index-cells = <0x01>;
			phandle = <0x7b>;
		};

		pcie0: pcie@4c300000 {
			compatible = "fsl,imx95-pcie";
			reg = <0x00 0x4c300000 0x00 0x10000 0x00 0x60100000 0x00 0xfe00000 0x00 0x4c360000 0x00 0x10000 0x00 0x4c340000 0x00 0x4000>;
			reg-names = "dbi", "config", "atu", "app";
			ranges = <0x81000000 0x00 0x00 0x00 0x6ff00000 0x00 0x100000 0x82000000 0x00 0x10000000 0x09 0x10000000 0x00 0x80000000>;
			#address-cells = <0x03>;
			#size-cells = <0x02>;
			device_type = "pci";
			linux,pci-domain = <0x00>;
			bus-range = <0x00 0xff>;
			num-lanes = <0x01>;
			num-viewport = <0x08>;
			interrupts = <0x00 0x136 0x04 0x00 0x137 0x04 0x00 0x136 0x04 0x00 0x136 0x04 0x00 0x136 0x04>;
			interrupt-names = "msi", "dma", "aer", "intr", "pme";
			#interrupt-cells = <0x01>;
			interrupt-map-mask = <0x00 0x00 0x00 0x07>;
			interrupt-map = <0x00 0x00 0x00 0x01 0x01 0x00 0x00 0x00 0x132 0x04 0x00 0x00 0x00 0x02 0x01 0x00 0x00 0x00 0x133 0x04 0x00 0x00 0x00 0x03 0x01 0x00 0x00 0x00 0x134 0x04 0x00 0x00 0x00 0x04 0x01 0x00 0x00 0x00 0x135 0x04>;
			clocks = <0x11 0x57 0x11 0x24 0x11 0x23 0x11 0x58 0x7d 0x00>;
			clock-names = "pcie", "pcie_bus", "pcie_phy", "pcie_aux", "ref";
			assigned-clocks = <0x11 0x23 0x11 0x24 0x11 0x58>;
			assigned-clock-rates = <0xd693a400 0x5f5e100 0x989680>;
			assigned-clock-parents = <0x00 0x00 0x11 0x0a>;
			power-domains = <0x51 0x0f>;
			msi-map = <0x00 0x7e 0x10 0x01 0x100 0x7e 0x11 0x07>;
			iommu-map = <0x00 0x27 0x10 0x01 0x100 0x27 0x11 0x07>;
			iommu-map-mask = <0x1ff>;
			fsl,max-link-speed = <0x03>;
			status = "okay";
			pinctrl-0 = <0x7f>;
			pinctrl-names = "default";
			reset-gpio = <0x2a 0x0d 0x01>;
			vpcie-supply = <0x80>;
			phandle = <0x12a>;
		};

		pcie0_ep: pcie-ep@4c300000 {
			compatible = "fsl,imx95-pcie-ep";
			reg = <0x00 0x4c300000 0x00 0x10000 0x00 0x4c360000 0x00 0x1000 0x00 0x4c320000 0x00 0x1000 0x00 0x4c340000 0x00 0x4000 0x00 0x4c370000 0x00 0x10000 0x09 0x00 0x01 0x00>;
			reg-names = "dbi", "atu", "dbi2", "app", "dma", "addr_space";
			num-lanes = <0x01>;
			interrupts = <0x00 0x137 0x04>;
			interrupt-names = "dma";
			clocks = <0x11 0x57 0x11 0x24 0x11 0x23 0x11 0x58>;
			clock-names = "pcie", "pcie_bus", "pcie_phy", "pcie_aux";
			assigned-clocks = <0x11 0x23 0x11 0x24 0x11 0x58>;
			assigned-clock-rates = <0xd693a400 0x5f5e100 0x989680>;
			assigned-clock-parents = <0x00 0x00 0x11 0x0a>;
			msi-map = <0x00 0x7e 0x10 0x01>;
			power-domains = <0x51 0x0f>;
			fsl,max-link-speed = <0x03>;
			status = "disabled";
			phandle = <0x12b>;
		};

		pcie1: pcie@4c380000 {
			compatible = "fsl,imx95-pcie";
			reg = <0x00 0x4c380000 0x00 0x10000 0x08 0x80100000 0x00 0xfe00000 0x00 0x4c3e0000 0x00 0x10000 0x00 0x4c3c0000 0x00 0x4000>;
			reg-names = "dbi", "config", "atu", "app";
			ranges = <0x81000000 0x00 0x00 0x08 0x8ff00000 0x00 0x100000 0x82000000 0x00 0x10000000 0x0a 0x10000000 0x00 0x80000000>;
			#address-cells = <0x03>;
			#size-cells = <0x02>;
			device_type = "pci";
			linux,pci-domain = <0x01>;
			bus-range = <0x00 0xff>;
			num-lanes = <0x01>;
			num-viewport = <0x08>;
			interrupts = <0x00 0x13c 0x04 0x00 0x13d 0x04 0x00 0x13c 0x04 0x00 0x13c 0x04 0x00 0x13c 0x04>;
			interrupt-names = "msi", "dma", "aer", "intr", "pme";
			#interrupt-cells = <0x01>;
			interrupt-map-mask = <0x00 0x00 0x00 0x07>;
			interrupt-map = <0x00 0x00 0x00 0x01 0x01 0x00 0x00 0x00 0x138 0x04 0x00 0x00 0x00 0x02 0x01 0x00 0x00 0x00 0x139 0x04 0x00 0x00 0x00 0x03 0x01 0x00 0x00 0x00 0x13a 0x04 0x00 0x00 0x00 0x04 0x01 0x00 0x00 0x00 0x13b 0x04>;
			clocks = <0x11 0x57 0x11 0x24 0x11 0x23 0x11 0x58 0x7d 0x00>;
			clock-names = "pcie", "pcie_bus", "pcie_phy", "pcie_aux", "ref";
			assigned-clocks = <0x11 0x23 0x11 0x24 0x11 0x58>;
			assigned-clock-rates = <0xd693a400 0x5f5e100 0x989680>;
			assigned-clock-parents = <0x00 0x00 0x11 0x0a>;
			power-domains = <0x51 0x0f>;
			msi-map = <0x00 0x7e 0x98 0x01 0x100 0x7e 0x99 0x07>;
			msi-map-mask = <0x1ff>;
			iommu-map = <0x00 0x27 0x18 0x01 0x100 0x27 0x19 0x07>;
			iommu-map-mask = <0x1ff>;
			fsl,max-link-speed = <0x03>;
			status = "disabled";
			phandle = <0x12c>;
		};

		pcie1_ep: pcie-ep@4c380000 {
			compatible = "fsl,imx95-pcie-ep";
			reg = <0x00 0x4c380000 0x00 0x10000 0x00 0x4c3e0000 0x00 0x1000 0x00 0x4c3a0000 0x00 0x1000 0x00 0x4c3c0000 0x00 0x4000 0x00 0x4c3f0000 0x00 0x10000 0x0a 0x00 0x01 0x00>;
			reg-names = "dbi", "atu", "dbi2", "app", "dma", "addr_space";
			num-lanes = <0x01>;
			interrupts = <0x00 0x13d 0x04>;
			interrupt-names = "dma";
			clocks = <0x11 0x57 0x11 0x24 0x11 0x23 0x11 0x58>;
			clock-names = "pcie", "pcie_bus", "pcie_phy", "pcie_aux";
			assigned-clocks = <0x11 0x23 0x11 0x24 0x11 0x58>;
			assigned-clock-rates = <0xd693a400 0x5f5e100 0x989680>;
			assigned-clock-parents = <0x00 0x00 0x11 0x0a>;
			msi-map = <0x00 0x7e 0x98 0x01>;
			power-domains = <0x51 0x0f>;
			fsl,max-link-speed = <0x03>;
			status = "disabled";
			phandle = <0x12d>;
		};

		vpu_blk_ctrl: clock-controller@4c410000 {
			compatible = "nxp,imx95-vpu-csr", "syscon";
			reg = <0x00 0x4c410000 0x00 0x10000>;
			#clock-cells = <0x01>;
			clocks = <0x11 0x72>;
			power-domains = <0x51 0x15>;
			assigned-clocks = <0x11 0x72 0x11 0x73 0x11 0x75>;
			assigned-clock-parents = <0x11 0x0a 0x11 0x0c 0x11 0x06>;
			assigned-clock-rates = <0x7f28155 0x27c19cc0 0x1dcd6500>;
			phandle = <0x81>;
		};

		jpegdec: jpegdec@4c500000 {
			compatible = "nxp,imx95-jpgdec", "nxp,imx8qxp-jpgdec";
			reg = <0x00 0x4c500000 0x00 0x50000>;
			interrupts = <0x00 0x127 0x04 0x00 0x128 0x04 0x00 0x129 0x04 0x00 0x12a 0x04>;
			clocks = <0x11 0x73 0x81 0x02>;
			assigned-clocks = <0x81 0x02>;
			assigned-clock-parents = <0x11 0x75>;
			power-domains = <0x51 0x15>;
			phandle = <0x12e>;
		};

		jpegenc: jpegenc@4c550000 {
			compatible = "nxp,imx95-jpgenc", "nxp,imx8qxp-jpgenc";
			reg = <0x00 0x4c550000 0x00 0x50000>;
			interrupts = <0x00 0x123 0x04 0x00 0x124 0x04 0x00 0x125 0x04 0x00 0x126 0x04>;
			clocks = <0x11 0x73 0x81 0x01>;
			assigned-clocks = <0x81 0x01>;
			assigned-clock-parents = <0x11 0x75>;
			power-domains = <0x51 0x15>;
			phandle = <0x12f>;
		};

		netcmix_blk_ctrl: syscon@4c810000 {
			compatible = "nxp,imx95-netcmix-blk-ctrl", "syscon";
			reg = <0x00 0x4c810000 0x00 0x08>;
			#clock-cells = <0x01>;
			clocks = <0x11 0x61>;
			assigned-clocks = <0x11 0x61>;
			assigned-clock-parents = <0x11 0x0a>;
			assigned-clock-rates = <0x7f28155>;
			power-domains = <0x51 0x12>;
			status = "okay";
			phandle = <0x130>;
		};

		sai2: sai@4c880000 {
			compatible = "fsl,imx95-sai";
			reg = <0x00 0x4c880000 0x00 0x10000>;
			interrupts = <0x00 0xa9 0x04>;
			clocks = <0x11 0x61 0x37 0x11 0x69 0x37 0x37>;
			clock-names = "bus", "mclk0", "mclk1", "mclk2", "mclk3";
			power-domains = <0x51 0x12>;
			dmas = <0x28 0x3b 0x00 0x01 0x28 0x3a 0x00 0x00>;
			dma-names = "rx", "tx";
			status = "disabled";
			phandle = <0x131>;
		};

		netc_blk_ctrl: system-controller@4cde0000 {
			compatible = "nxp,imx95-netc-blk-ctrl";
			reg = <0x00 0x4cde0000 0x00 0x10000 0x00 0x4cdf0000 0x00 0x10000 0x00 0x4c81000c 0x00 0x18>;
			reg-names = "ierb", "prb", "netcmix";
			#address-cells = <0x02>;
			#size-cells = <0x02>;
			ranges;
			power-domains = <0x51 0x12>;
			assigned-clocks = <0x11 0x62 0x11 0x66>;
			assigned-clock-parents = <0x11 0x0c 0x11 0x06>;
			assigned-clock-rates = <0x27bc86aa 0xee6b280>;
			clocks = <0x11 0x62>;
			clock-names = "ipg";
			status = "okay";
			phandle = <0x132>;

			netc_bus0: pcie@4ca00000 {
				compatible = "pci-host-ecam-generic";
				reg = <0x00 0x4ca00000 0x00 0x100000>;
				#address-cells = <0x03>;
				#size-cells = <0x02>;
				device_type = "pci";
				bus-range = <0x00 0x00>;
				msi-map = <0x00 0x7e 0x60 0x01 0x10 0x7e 0x61 0x01 0x20 0x7e 0x62 0x01 0x40 0x7e 0x63 0x01 0x50 0x7e 0x65 0x01 0x60 0x7e 0x66 0x01 0x80 0x7e 0x64 0x01 0xc0 0x7e 0x67 0x01>;
				iommu-map = <0x00 0x27 0x20 0x01 0x10 0x27 0x21 0x01 0x20 0x27 0x22 0x01 0x40 0x27 0x23 0x01 0x50 0x27 0x25 0x01 0x60 0x27 0x26 0x01 0x80 0x27 0x24 0x01 0xc0 0x27 0x27 0x01>;
				ranges = <0x82000000 0x00 0x4cc00000 0x00 0x4cc00000 0x00 0xe0000 0xc2000000 0x00 0x4cd00000 0x00 0x4cd00000 0x00 0x10000 0x82000000 0x00 0x4cd20000 0x00 0x4cd20000 0x00 0x60000 0xc2000000 0x00 0x4cd80000 0x00 0x4cd80000 0x00 0x60000>;
				#interrupt-cells = <0x01>;
				interrupt-map-mask = <0x00 0x00 0x00 0x07>;
				interrupt-map = <0x00 0x00 0x00 0x01 0x01 0x00 0x00 0x00 0x130 0x04>;
				phandle = <0x133>;

				enetc_port0: ethernet@0,0 {
					compatible = "pci1131,e101";
					reg = <0x00 0x00 0x00 0x00 0x00>;
					clocks = <0x11 0x66>;
					clock-names = "ref";
					nvmem-cells = <0x82>;
					nvmem-cell-names = "mac-address";
					status = "okay";
					pinctrl-names = "default";
					pinctrl-0 = <0x83>;
					phy-handle = <0x84>;
					phy-mode = "rgmii-id";
					phandle = <0x134>;
				};

				enetc_port1: ethernet@8,0 {
					compatible = "pci1131,e101";
					reg = <0x4000 0x00 0x00 0x00 0x00>;
					clocks = <0x11 0x66>;
					clock-names = "ref";
					nvmem-cells = <0x85>;
					nvmem-cell-names = "mac-address";
					status = "okay";
					pinctrl-names = "default";
					pinctrl-0 = <0x86>;
					phy-handle = <0x87>;
					phy-mode = "rgmii-id";
					phandle = <0x135>;
				};

				enetc_port2: ethernet@10,0 {
					compatible = "pci1131,e101";
					reg = <0x8000 0x00 0x00 0x00 0x00>;
					nvmem-cells = <0x88>;
					nvmem-cell-names = "mac-address";
					status = "disabled";
					phandle = <0x136>;
				};

				netc_timer: ethernet@18,0 {
					compatible = "pci1131,ee02";
					reg = <0xc000 0x00 0x00 0x00 0x00>;
					status = "okay";
					phandle = <0x137>;
				};

				rcec@1,0 {
					reg = <0x800 0x00 0x00 0x00 0x00>;
					interrupts = <0x01>;
				};
			};

			netc_bus1: pcie@4cb00000 {
				compatible = "pci-host-ecam-generic";
				reg = <0x00 0x4cb00000 0x00 0x100000>;
				#address-cells = <0x03>;
				#size-cells = <0x02>;
				device_type = "pci";
				bus-range = <0x01 0x01>;
				ranges = <0x82000000 0x00 0x4cce0000 0x00 0x4cce0000 0x00 0x20000 0xc2000000 0x00 0x4cd10000 0x00 0x4cd10000 0x00 0x10000>;
				#interrupt-cells = <0x01>;
				interrupt-map-mask = <0x00 0x00 0x00 0x07>;
				interrupt-map = <0x00 0x00 0x00 0x01 0x01 0x00 0x00 0x00 0x131 0x04>;
				phandle = <0x138>;

				netc_emdio: mdio@0,0 {
					compatible = "pci1131,ee00";
					reg = <0x10000 0x00 0x00 0x00 0x00>;
					#address-cells = <0x01>;
					#size-cells = <0x00>;
					status = "okay";
					pinctrl-names = "default";
					pinctrl-0 = <0x89>;
					phandle = <0x139>;

					ethphy0: ethernet-phy@1 {
						reg = <0x01>;
						reset-gpios = <0x2f 0x00 0x01>;
						reset-assert-us = <0x2710>;
						reset-deassert-us = <0x13880>;
						phandle = <0x84>;
					};

					ethphy1: ethernet-phy@2 {
						reg = <0x02>;
						reset-gpios = <0x2f 0x01 0x01>;
						reset-assert-us = <0x2710>;
						reset-deassert-us = <0x13880>;
						phandle = <0x87>;
					};
				};

				rcec@1,0 {
					reg = <0x10800 0x00 0x00 0x00 0x00>;
					interrupts = <0x01>;
				};
			};
		};

		ddr-pmu@4e090dc0 {
			compatible = "fsl,imx95-ddr-pmu", "fsl,imx93-ddr-pmu";
			reg = <0x00 0x4e090dc0 0x00 0x200>;
			interrupts = <0x00 0x5b 0x04>;
		};

		mali: gpu@4d900000 {
			compatible = "arm,mali-valhall", "nxp,imx95-mali";
			reg = <0x00 0x4d900000 0x00 0x480000>;
			reg-names = "gpu_base";
			interrupts = <0x00 0x120 0x04 0x00 0x121 0x04 0x00 0x122 0x04>;
			interrupt-names = "gpu", "job", "mmu";
			clocks = <0x11 0xae>;
			clock-names = "gpu";
			power-domains = <0x51 0x0e 0x03 0x09>;
			power-domain-names = "gpumix", "gpuperf";
			operating-points-v2 = <0x8a>;
			#cooling-cells = <0x02>;
			phandle = <0x1b>;

			simple_power: power_model@0 {
				compatible = "arm,mali-simple-power-model";
				static-coefficient = <0xe6c1>;
				dynamic-coefficient = <0x3f5>;
				reference_voltage = <0x398>;
				ts = <0x4e20 0x7d0 0xffffffec 0x02>;
				thermal-zone = "ana-thermal";
				phandle = <0x13a>;
			};

			ipa_power: power_model@1 {
				compatible = "arm,mali-tvax-power-model";
				reference_voltage = <0x398>;
				phandle = <0x13b>;
			};
		};

		vpu0: vpu@4c480000 {
			compatible = "fsl,cnm633c-vpu";
			reg = <0x00 0x4c480000 0x00 0x10000>;
			interrupts = <0x00 0x12b 0x04>;
			clocks = <0x11 0x73 0x81 0x00>;
			clock-names = "vpu", "vpublk_wave";
			power-domains = <0x51 0x15>;
			cnm,ctrl = <0x1c>;
			phandle = <0x13c>;
		};

		vpu1: vpu@4c490000 {
			compatible = "fsl,cnm633c-vpu";
			reg = <0x00 0x4c490000 0x00 0x10000>;
			interrupts = <0x00 0x12c 0x04>;
			clocks = <0x11 0x73 0x81 0x00>;
			clock-names = "vpu", "vpublk_wave";
			power-domains = <0x51 0x15>;
			cnm,ctrl = <0x1c>;
			status = "disabled";
			phandle = <0x13d>;
		};

		vpu2: vpu@4c4a0000 {
			compatible = "fsl,cnm633c-vpu";
			reg = <0x00 0x4c4a0000 0x00 0x10000>;
			interrupts = <0x00 0x12d 0x04>;
			clocks = <0x11 0x73 0x81 0x00>;
			clock-names = "vpu", "vpublk_wave";
			power-domains = <0x51 0x15>;
			cnm,ctrl = <0x1c>;
			status = "disabled";
			phandle = <0x13e>;
		};

		vpu3: vpu@4c4b0000 {
			compatible = "fsl,cnm633c-vpu";
			reg = <0x00 0x4c4b0000 0x00 0x10000>;
			interrupts = <0x00 0x12e 0x04>;
			clocks = <0x11 0x73 0x81 0x00>;
			clock-names = "vpu", "vpublk_wave";
			power-domains = <0x51 0x15>;
			cnm,ctrl = <0x1c>;
			status = "disabled";
			phandle = <0x13f>;
		};

		vpuctrl: vpu-ctrl@4c4c0000 {
			compatible = "fsl,cm633c-vpu-ctrl";
			reg = <0x00 0x4c4c0000 0x00 0x10000>;
			clocks = <0x11 0x73 0x81 0x00>;
			clock-names = "vpu", "vpublk_wave";
			power-domains = <0x51 0x15 0x03 0x0a>;
			power-domain-names = "vpumix", "vpuperf";
			#cooling-cells = <0x02>;
			boot = <0x8b>;
			sram = <0x8c>;
			phandle = <0x1c>;
		};

		neutron_core: imx95-neutron-remoteproc@4ab00000 {
			compatible = "fsl,imx95-neutron-rproc";
			reg = <0x00 0x4ab00000 0x00 0x04>;
			power-domains = <0x51 0x14>;
			phandle = <0x8d>;
		};

		neutron: imx95-neutron@4ab00004 {
			compatible = "fsl,imx95-neutron";
			reg = <0x00 0x4ab00004 0x00 0x400>;
			fsl,neutron-rproc = <0x8d>;
			interrupts = <0x00 0x13e 0x04>;
			clocks = <0x11 0x6d 0x11 0x6c>;
			clock-names = "npu", "npu_apb";
			power-domains = <0x51 0x14>;
			iommus = <0x27 0x0d>;
			phandle = <0x140>;
		};
	};

	rpmsg-lifecycle {
		compatible = "nxp,rpmsg-lifecycle";
	};

	ele_if0: secure-enclave-0 {
		compatible = "fsl,imx95-se";
		mbox-names = "tx", "rx";
		mboxes = <0x8e 0x00 0x00 0x8e 0x01 0x00>;
		memory-region = <0x8f>;
		phandle = <0x141>;
	};

	v2x_dbg: secure-enclave-1 {
		compatible = "fsl,imx95-se";
		mbox-names = "tx", "rx";
		mboxes = <0x90 0x00 0x00 0x90 0x01 0x00>;
		phandle = <0x142>;
	};

	v2x_sv0: secure-enclave-2 {
		compatible = "fsl,imx95-se";
		mbox-names = "tx", "rx";
		mboxes = <0x91 0x00 0x00 0x91 0x01 0x00>;
		phandle = <0x143>;
	};

	v2x_she: secure-enclave-3 {
		compatible = "fsl,imx95-se";
		mbox-names = "tx", "rx";
		mboxes = <0x92 0x00 0x00 0x92 0x01 0x00>;
		phandle = <0x144>;
	};

	v2x_sg0: secure-enclave-4 {
		compatible = "fsl,imx95-se";
		mbox-names = "tx", "rx";
		mboxes = <0x93 0x00 0x00 0x93 0x01 0x00>;
		phandle = <0x145>;
	};

	v2x_sg1: secure-enclave-5 {
		compatible = "fsl,imx95-se";
		mbox-names = "tx", "rx";
		mboxes = <0x94 0x00 0x00 0x94 0x01 0x00>;
		phandle = <0x146>;
	};

	bt_sco_codec: bt-sco-codec {
		compatible = "linux,bt-sco";
		#sound-dai-cells = <0x01>;
		phandle = <0xa3>;
	};

	chosen {
		stdout-path = "/soc/bus@44000000/serial@44380000";
		#address-cells = <0x02>;
		#size-cells = <0x02>;
	};

	dmic: dmic {
		compatible = "dmic-codec";
		#sound-dai-cells = <0x00>;
		num-channels = <0x02>;
		phandle = <0xa6>;
	};

	hdmi-connector {
		compatible = "hdmi-connector";
		label = "hdmi";
		type = "a";

		port {

			hdmi_connector_in: endpoint {
				remote-endpoint = <0x95>;
				phandle = <0x31>;
			};
		};
	};

	memory@80000000 {
		device_type = "memory";
		reg = <0x00 0x80000000 0x00 0x80000000>;
	};

	reserved-memory {
		#address-cells = <0x02>;
		#size-cells = <0x02>;
		ranges;

		dbg_shm: dbg-shm@20484000 {
			phandle = <0x14f>;
			no-map;
			reg = <0x00 0x20484000 0x00 0x2000>;
		};

		ipc_shm: ipc-shm@20480000 {
			phandle = <0x14e>;
			no-map;
			reg = <0x00 0x20480000 0x00 0x4000>;
		};

		linux_cma: linux,cma {
			compatible = "shared-dma-pool";
			reusable;
			size = <0x00 0x3c000000>;
			alloc-ranges = <0x00 0x80000000 0x00 0x7f000000>;
			linux,cma-default;
			phandle = <0x147>;
		};

		vpu_boot: vpu_boot@a0000000 {
			reg = <0x00 0xa0000000 0x00 0x100000>;
			no-map;
			phandle = <0x8b>;
		};

		vdev0vring0: vdev0vring0@88000000 {
			reg = <0x00 0x88000000 0x00 0x8000>;
			no-map;
			phandle = <0x9d>;
		};

		vdev0vring1: vdev0vring1@88008000 {
			reg = <0x00 0x88008000 0x00 0x8000>;
			no-map;
			phandle = <0x9e>;
		};

		vdev1vring0: vdev1vring0@88010000 {
			reg = <0x00 0x88010000 0x00 0x8000>;
			no-map;
			phandle = <0x9f>;
		};

		vdev1vring1: vdev1vring1@88018000 {
			reg = <0x00 0x88018000 0x00 0x8000>;
			no-map;
			phandle = <0xa0>;
		};

		rsc_table: rsc-table@88220000 {
			reg = <0x00 0x88220000 0x00 0x1000>;
			no-map;
			phandle = <0xa1>;
		};

		vdevbuffer: vdevbuffer@88020000 {
			compatible = "shared-dma-pool";
			reg = <0x00 0x88020000 0x00 0x100000>;
			no-map;
			phandle = <0x9c>;
		};

		ele_reserved: ele-reserved@a4120000 {
			compatible = "shared-dma-pool";
			reg = <0x00 0xa4120000 0x00 0x100000>;
			no-map;
			phandle = <0x8f>;
		};
	};

	reg_1p8v: regulator-1p8v {
		compatible = "regulator-fixed";
		regulator-max-microvolt = <0x1b7740>;
		regulator-min-microvolt = <0x1b7740>;
		regulator-name = "+V1.8_SW";
		phandle = <0x148>;
	};

	reg_3p3v: regulator-3p3v {
		compatible = "regulator-fixed";
		regulator-max-microvolt = <0x325aa0>;
		regulator-min-microvolt = <0x325aa0>;
		regulator-name = "+V3.3_SW";
		phandle = <0x149>;
	};

	reg_5p0v: regulator-5p0v {
		compatible = "regulator-fixed";
		regulator-max-microvolt = <0x4c4b40>;
		regulator-min-microvolt = <0x4c4b40>;
		regulator-name = "+V5.0_SW";
		phandle = <0x14a>;
	};

	reg_can_stby: regulator-can-stby {
		compatible = "regulator-fixed";
		regulator-name = "can-stby";
		regulator-min-microvolt = <0x325aa0>;
		regulator-max-microvolt = <0x325aa0>;
		gpio = <0x2f 0x07 0x01>;
		enable-active-low;
		phandle = <0x36>;
	};

	reg_ext_3v3: regulator-ext-3v3 {
		compatible = "regulator-fixed";
		regulator-max-microvolt = <0x325aa0>;
		regulator-min-microvolt = <0x325aa0>;
		regulator-name = "VCCEXT_3V3";
		gpio = <0x2f 0x0d 0x00>;
		enable-active-high;
		regulator-always-on;
		phandle = <0x14b>;
	};

	reg_ext_5v: regulator-ext-5v {
		compatible = "regulator-fixed";
		regulator-max-microvolt = <0x4c4b40>;
		regulator-min-microvolt = <0x4c4b40>;
		regulator-name = "VCCEXT_5V";
		gpio = <0x2f 0x0c 0x00>;
		enable-active-high;
		regulator-always-on;
		phandle = <0x96>;
	};

	reg_ext_12v: regulator-ext-12v {
		compatible = "regulator-fixed";
		regulator-max-microvolt = <0xb71b00>;
		regulator-min-microvolt = <0xb71b00>;
		regulator-name = "VCCEXT_12V";
		vin-supply = <0x96>;
		phandle = <0x14c>;
	};

	reg_usdhc2_vmmc: regulator-usdhc2 {
		compatible = "regulator-fixed";
		pinctrl-names = "default";
		pinctrl-0 = <0x97>;
		regulator-name = "VDD_SD2_3V3";
		regulator-min-microvolt = <0x325aa0>;
		regulator-max-microvolt = <0x325aa0>;
		gpio = <0x41 0x07 0x00>;
		off-on-delay-us = <0x2ee0>;
		enable-active-high;
		phandle = <0x42>;
	};

	reg_usb_vbus: regulator-vbus {
		compatible = "regulator-fixed";
		regulator-name = "USB_VBUS";
		regulator-min-microvolt = <0x4c4b40>;
		regulator-max-microvolt = <0x4c4b40>;
		gpio = <0x2f 0x0f 0x00>;
		enable-active-high;
		phandle = <0x7c>;
	};

	usdhc3_pwrseq: usdhc3-pwrseq {
		compatible = "mmc-pwrseq-simple";
		reset-gpios = <0x2f 0x08 0x01>;
		phandle = <0x46>;
	};

	reg_usdhc3_vmmc: regulator-usdhc3 {
		compatible = "regulator-fixed";
		regulator-name = "WLAN_EN";
		regulator-min-microvolt = <0x325aa0>;
		regulator-max-microvolt = <0x325aa0>;
		vin-supply = <0x98>;
		gpio = <0x2f 0x09 0x00>;
		startup-delay-us = <0x4e20>;
		enable-active-high;
		phandle = <0x47>;
	};

	reg_vref_1v8: regulator-adc-vref {
		compatible = "regulator-fixed";
		regulator-name = "vref_1v8";
		regulator-min-microvolt = <0x1b7740>;
		regulator-max-microvolt = <0x1b7740>;
		phandle = <0x50>;
	};

	reg_m2_ekey_pwr: regulator-m2-pwr {
		compatible = "regulator-fixed";
		pinctrl-names = "default";
		pinctrl-0 = <0x99>;
		regulator-name = "M.2-power-ekey";
		regulator-min-microvolt = <0x325aa0>;
		regulator-max-microvolt = <0x325aa0>;
		gpio = <0x2f 0x10 0x00>;
		enable-active-high;
		phandle = <0x98>;
	};

	reg_m2_mkey_pwr: regulator-m2-mkey-pwr {
		compatible = "regulator-fixed";
		pinctrl-names = "default";
		pinctrl-0 = <0x9a>;
		regulator-name = "M.2-power-mkey";
		regulator-min-microvolt = <0x325aa0>;
		regulator-max-microvolt = <0x325aa0>;
		gpio = <0x2f 0x0e 0x00>;
		enable-active-high;
		phandle = <0x80>;
	};

	cm7: imx95-cm7 {
		compatible = "fsl,imx95-cm7";
		mbox-names = "tx", "rx", "rxdb";
		mboxes = <0x9b 0x00 0x01 0x9b 0x01 0x01 0x9b 0x03 0x01>;
		memory-region = <0x9c 0x9d 0x9e 0x9f 0xa0 0xa1>;
		fsl,cpu-id = <0x01>;
		fsl,lmm-id = <0x01>;
		fsl,startup-delay-ms = <0x32>;
		status = "okay";
		phandle = <0x14d>;
	};

	sound-bt-sco {
		compatible = "simple-audio-card";
		simple-audio-card,bitclock-inversion;
		simple-audio-card,bitclock-master = <0xa2>;
		simple-audio-card,format = "dsp_a";
		simple-audio-card,frame-master = <0xa2>;
		simple-audio-card,name = "bt-sco-audio";

		simple-audio-card,codec {
			sound-dai = <0xa3 0x01>;
		};

		btcpu: simple-audio-card,cpu {
			dai-tdm-slot-num = <0x02>;
			dai-tdm-slot-width = <0x10>;
			sound-dai = <0xa4>;
			phandle = <0xa2>;
		};
	};

	sound-micfil {
		compatible = "fsl,imx-audio-card";
		model = "micfil-audio";

		pri-dai-link {
			link-name = "micfil hifi";
			format = "i2s";

			cpu {
				sound-dai = <0xa5>;
			};

			codec {
				sound-dai = <0xa6>;
			};
		};
	};

	sound-mqs {
		compatible = "audio-graph-card2";
		links = <0xa7>;
		label = "mqs-audio";
	};

	__symbols__ {
		dbg_shm = "/reserved-memory/dbg-shm@20484000";
		ipc_shm = "/reserved-memory/ipc-shm@20480000";
		cpu_pd_wait = "/cpus/idle-states/cpu-pd-wait";
		A55_0 = "/cpus/cpu@0";
		A55_1 = "/cpus/cpu@100";
		A55_2 = "/cpus/cpu@200";
		A55_3 = "/cpus/cpu@300";
		A55_4 = "/cpus/cpu@400";
		A55_5 = "/cpus/cpu@500";
		l2_cache_l0 = "/cpus/l2-cache-l0";
		l2_cache_l1 = "/cpus/l2-cache-l1";
		l2_cache_l2 = "/cpus/l2-cache-l2";
		l2_cache_l3 = "/cpus/l2-cache-l3";
		l2_cache_l4 = "/cpus/l2-cache-l4";
		l2_cache_l5 = "/cpus/l2-cache-l5";
		l3_cache = "/cpus/l3-cache";
		reg_dummy = "/reg_dummy";
		dummy = "/clock-dummy";
		clk_ext1 = "/clock-ext1";
		sai1_mclk = "/clock-sai-mclk1";
		sai2_mclk = "/clock-sai-mclk2";
		sai3_mclk = "/clock-sai-mclk3";
		sai4_mclk = "/clock-sai-mclk4";
		sai5_mclk = "/clock-sai-mclk5";
		clk_sys100m = "/clock-sys100m";
		osc_24m = "/clock-24m";
		ldb_pll_pixel = "/ldb_pll_div7";
		mqs1 = "/mqs1";
		mqs1_port = "/mqs1/port";
		mqs1_endpoint = "/mqs1/port/endpoint";
		mqs2 = "/mqs2";
		sram1 = "/sram@204c0000";
		scmi_devpd = "/firmware/scmi/protocol@11";
		scmi_sys_power = "/firmware/scmi/protocol@12";
		scmi_perf = "/firmware/scmi/protocol@13";
		scmi_clk = "/firmware/scmi/protocol@14";
		scmi_sensor = "/firmware/scmi/protocol@15";
		scmi_iomuxc = "/firmware/scmi/protocol@19";
		pinctrl_hog = "/firmware/scmi/protocol@19/hoggrp";
		pinctrl_flexcan2 = "/firmware/scmi/protocol@19/flexcan2grp";
		pinctrl_flexcan5 = "/firmware/scmi/protocol@19/flexcan5grp";
		pinctrl_lpi2c1 = "/firmware/scmi/protocol@19/lpi2c1grp";
		pinctrl_lpi2c2 = "/firmware/scmi/protocol@19/lpi2c2grp";
		pinctrl_lpi2c3 = "/firmware/scmi/protocol@19/lpi2c3grp";
		pinctrl_lpi2c4 = "/firmware/scmi/protocol@19/lpi2c4grp";
		pinctrl_pcal6524 = "/firmware/scmi/protocol@19/pcal6524grp";
		pinctrl_uart1 = "/firmware/scmi/protocol@19/uart1grp";
		pinctrl_uart5 = "/firmware/scmi/protocol@19/uart5grp";
		pinctrl_enetc0 = "/firmware/scmi/protocol@19/enetc0grp";
		pinctrl_enetc1 = "/firmware/scmi/protocol@19/enetc1grp";
		pinctrl_emdio = "/firmware/scmi/protocol@19/emdiogrp";
		pinctrl_mipi_dsi_csi = "/firmware/scmi/protocol@19/mipidsigrp";
		pinctrl_ekey_pwr = "/firmware/scmi/protocol@19/ekeypwrgrp";
		pinctrl_mkey_pwr = "/firmware/scmi/protocol@19/mkeypwrgrp";
		pinctrl_mqs1 = "/firmware/scmi/protocol@19/mqs1grp";
		pinctrl_pcie0 = "/firmware/scmi/protocol@19/pcie0grp";
		pinctrl_pdm = "/firmware/scmi/protocol@19/pdmgrp";
		pinctrl_ptn5110 = "/firmware/scmi/protocol@19/ptn5110grp";
		pinctrl_sai5 = "/firmware/scmi/protocol@19/sai5grp";
		pinctrl_usdhc1 = "/firmware/scmi/protocol@19/usdhc1grp";
		pinctrl_usdhc1_100mhz = "/firmware/scmi/protocol@19/usdhc1-100mhzgrp";
		pinctrl_usdhc1_200mhz = "/firmware/scmi/protocol@19/usdhc1-200mhzgrp";
		pinctrl_reg_usdhc2_vmmc = "/firmware/scmi/protocol@19/regusdhc2vmmcgrp";
		pinctrl_reg_ext_pwr = "/firmware/scmi/protocol@19/regextpwrengrp";
		pinctrl_lpspi3 = "/firmware/scmi/protocol@19/lpspi3grp";
		pinctrl_usdhc2_gpio = "/firmware/scmi/protocol@19/usdhc2gpiogrp";
		pinctrl_usdhc2 = "/firmware/scmi/protocol@19/usdhc2grp";
		pinctrl_usdhc2_100mhz = "/firmware/scmi/protocol@19/usdhc2-100mhzgrp";
		pinctrl_usdhc2_200mhz = "/firmware/scmi/protocol@19/usdhc2-200mhzgrp";
		pinctrl_usdhc3 = "/firmware/scmi/protocol@19/usdhc3grp";
		pinctrl_usdhc3_100mhz = "/firmware/scmi/protocol@19/usdhc3-100mhzgrp";
		pinctrl_usdhc3_200mhz = "/firmware/scmi/protocol@19/usdhc3-200mhzgrp";
		scmi_lmm = "/firmware/scmi/protocol@80";
		scmi_bbm = "/firmware/scmi/protocol@81";
		scmi_cpu = "/firmware/scmi/protocol@82";
		scmi_misc = "/firmware/scmi/protocol@84";
		thermal_zones = "/thermal-zones";
		cpu_alert0 = "/thermal-zones/a55-thermal/trips/trip0";
		cpu_crit0 = "/thermal-zones/a55-thermal/trips/trip1";
		ana_alert = "/thermal-zones/ana-thermal/trips/trip0";
		ana_crit0 = "/thermal-zones/ana-thermal/trips/trip1";
		pf09_alert = "/thermal-zones/pf09/trips/trip0";
		pf09_crit = "/thermal-zones/pf09/trips/trip1";
		pf5301_alert = "/thermal-zones/pf53_arm/trips/trip0";
		pf5301_crit = "/thermal-zones/pf53_arm/trips/trip1";
		pf5302_alert = "/thermal-zones/pf53_soc/trips/trip0";
		pf5302_crit = "/thermal-zones/pf53_soc/trips/trip1";
		gic = "/interrupt-controller@48000000";
		its = "/interrupt-controller@48000000/msi-controller@48040000";
		gpu_opp_table = "/opp_table";
		usbphynop = "/usbphynop";
		imx95_soc = "/imx95-soc";
		etm0 = "/soc/etm@40840000";
		etm0_out_port = "/soc/etm@40840000/out-ports/port/endpoint";
		funnel0 = "/soc/funnel";
		ca_funnel_in_port0 = "/soc/funnel/in-ports/port/endpoint";
		ca_funnel_out_port0 = "/soc/funnel/out-ports/port/endpoint";
		funnel1 = "/soc/funnel-sys";
		hugo_funnel_in_port0 = "/soc/funnel-sys/in-ports/port/endpoint";
		hugo_funnel_out_port0 = "/soc/funnel-sys/out-ports/port/endpoint";
		etf = "/soc/etf@41030000";
		etf_in_port = "/soc/etf@41030000/in-ports/port/endpoint";
		etf_out_port = "/soc/etf@41030000/out-ports/port/endpoint";
		etr = "/soc/etr@41040000";
		etr_in_port = "/soc/etr@41040000/in-ports/port/endpoint";
		aips2 = "/soc/bus@42000000";
		edma2 = "/soc/bus@42000000/dma-controller@42000000";
		edma3 = "/soc/bus@42000000/dma-controller@42210000";
		mu7 = "/soc/bus@42000000/mailbox@42430000";
		wdog3 = "/soc/bus@42000000/watchdog@42490000";
		tpm3 = "/soc/bus@42000000/pwm@424e0000";
		tpm4 = "/soc/bus@42000000/pwm@424f0000";
		tpm5 = "/soc/bus@42000000/pwm@42500000";
		tpm6 = "/soc/bus@42000000/pwm@42510000";
		i3c2 = "/soc/bus@42000000/i3c@42520000";
		lpi2c3 = "/soc/bus@42000000/i2c@42530000";
		ptn5110 = "/soc/bus@42000000/i2c@42530000/tcpc@50";
		typec_con = "/soc/bus@42000000/i2c@42530000/tcpc@50/connector";
		typec_con_hs = "/soc/bus@42000000/i2c@42530000/tcpc@50/connector/ports/port@0/endpoint";
		typec_con_ss = "/soc/bus@42000000/i2c@42530000/tcpc@50/connector/ports/port@1/endpoint";
		lpi2c4 = "/soc/bus@42000000/i2c@42540000";
		pca9632 = "/soc/bus@42000000/i2c@42540000/pca9632@62";
		led_backlight0 = "/soc/bus@42000000/i2c@42540000/pca9632@62/led@0";
		led_backlight1 = "/soc/bus@42000000/i2c@42540000/pca9632@62/led@1";
		it6263_in = "/soc/bus@42000000/i2c@42540000/bridge@4c/ports/port@0/endpoint";
		it6263_out = "/soc/bus@42000000/i2c@42540000/bridge@4c/ports/port@1/endpoint";
		lpspi3 = "/soc/bus@42000000/spi@42550000";
		spidev0 = "/soc/bus@42000000/spi@42550000/spi@0";
		lpspi4 = "/soc/bus@42000000/spi@42560000";
		lpuart3 = "/soc/bus@42000000/serial@42570000";
		lpuart4 = "/soc/bus@42000000/serial@42580000";
		lpuart5 = "/soc/bus@42000000/serial@42590000";
		lpuart6 = "/soc/bus@42000000/serial@425a0000";
		flexcan2 = "/soc/bus@42000000/can@425b0000";
		flexcan3 = "/soc/bus@42000000/can@42600000";
		flexspi1 = "/soc/bus@42000000/spi@425e0000";
		sai3 = "/soc/bus@42000000/sai@42650000";
		sai4 = "/soc/bus@42000000/sai@42660000";
		sai5 = "/soc/bus@42000000/sai@42670000";
		xcvr = "/soc/bus@42000000/xcvr@42680000";
		flexio_i2c_master = "/soc/bus@42000000/flexio@425c0000";
		lpuart7 = "/soc/bus@42000000/serial@42690000";
		lpuart8 = "/soc/bus@42000000/serial@426a0000";
		lpi2c5 = "/soc/bus@42000000/i2c@426b0000";
		lpi2c6 = "/soc/bus@42000000/i2c@426c0000";
		lpi2c7 = "/soc/bus@42000000/i2c@426d0000";
		lpi2c8 = "/soc/bus@42000000/i2c@426e0000";
		lpspi5 = "/soc/bus@42000000/spi@426f0000";
		lpspi6 = "/soc/bus@42000000/spi@42700000";
		lpspi7 = "/soc/bus@42000000/spi@42710000";
		lpspi8 = "/soc/bus@42000000/spi@42720000";
		mu8 = "/soc/bus@42000000/mailbox@42730000";
		flexcan4 = "/soc/bus@42000000/can@427c0000";
		flexcan5 = "/soc/bus@42000000/can@427d0000";
		aips3 = "/soc/bus@42800000";
		usdhc1 = "/soc/bus@42800000/mmc@42850000";
		usdhc2 = "/soc/bus@42800000/mmc@42860000";
		usdhc3 = "/soc/bus@42800000/mmc@428b0000";
		gpio2 = "/soc/gpio@43810000";
		gpio3 = "/soc/gpio@43820000";
		gpio4 = "/soc/gpio@43840000";
		gpio5 = "/soc/gpio@43850000";
		aips1 = "/soc/bus@44000000";
		edma1 = "/soc/bus@44000000/dma-controller@44000000";
		mu1 = "/soc/bus@44000000/mailbox@44220000";
		system_counter = "/soc/bus@44000000/timer@44290000";
		tpm1 = "/soc/bus@44000000/pwm@44310000";
		tpm2 = "/soc/bus@44000000/pwm@44320000";
		i3c1 = "/soc/bus@44000000/i3c@44330000";
		lpi2c1 = "/soc/bus@44000000/i2c@44340000";
		lpi2c2 = "/soc/bus@44000000/i2c@44350000";
		pcal6524 = "/soc/bus@44000000/i2c@44350000/gpio@22";
		pcal6408_b = "/soc/bus@44000000/i2c@44350000/gpio@20";
		lpspi1 = "/soc/bus@44000000/spi@44360000";
		lpspi2 = "/soc/bus@44000000/spi@44370000";
		lpuart1 = "/soc/bus@44000000/serial@44380000";
		lpuart2 = "/soc/bus@44000000/serial@44390000";
		flexcan1 = "/soc/bus@44000000/can@443a0000";
		sai1 = "/soc/bus@44000000/sai@443b0000";
		sai1_port1 = "/soc/bus@44000000/sai@443b0000/ports/port@1";
		sai1_endpoint1 = "/soc/bus@44000000/sai@443b0000/ports/port@1/endpoint";
		micfil = "/soc/bus@44000000/micfil@44520000";
		adc1 = "/soc/bus@44000000/adc@44530000";
		mu2 = "/soc/bus@44000000/mailbox@445b0000";
		sram0 = "/soc/bus@44000000/mailbox@445b0000/sram@445b1000";
		scmi_buf0 = "/soc/bus@44000000/mailbox@445b0000/sram@445b1000/scmi-sram-section@0";
		scmi_buf1 = "/soc/bus@44000000/mailbox@445b0000/sram@445b1000/scmi-sram-section@80";
		mu3 = "/soc/bus@44000000/mailbox@445d0000";
		mu4 = "/soc/bus@44000000/mailbox@445f0000";
		mu6 = "/soc/bus@44000000/mailbox@44630000";
		v2x_mu4 = "/soc/mailbox@47300000";
		v2x_mu6 = "/soc/mailbox@47320000";
		v2x_mu7 = "/soc/mailbox@47330000";
		v2x_mu8 = "/soc/mailbox@47340000";
		v2x_mu = "/soc/mailbox@47350000";
		gpio1 = "/soc/gpio@47400000";
		ocotp = "/soc/efuse@47510000";
		eth_mac0 = "/soc/efuse@47510000/mac-address@0";
		eth_mac1 = "/soc/efuse@47510000/mac-address@1";
		eth_mac2 = "/soc/efuse@47510000/mac-address@2";
		elemu0 = "/soc/mailbox@47520000";
		elemu1 = "/soc/mailbox@47530000";
		elemu2 = "/soc/mailbox@47540000";
		elemu3 = "/soc/mailbox@47550000";
		elemu4 = "/soc/mailbox@47560000";
		elemu5 = "/soc/mailbox@47570000";
		aips4 = "/soc/bus@49000000";
		smmu = "/soc/bus@49000000/iommu@490d0000";
		cameramix_csr = "/soc/syscon@4ac10000";
		csi_pixel_formatter_0 = "/soc/syscon@4ac10000/formatter@20";
		csi_pixel_formatter_1 = "/soc/syscon@4ac10000/formatter@120";
		cameramix_mu1 = "/soc/mailbox@4ac60000";
		cameramix_mu2 = "/soc/mailbox@4ac70000";
		cameramix_mu3 = "/soc/mailbox@4ac80000";
		cameramix_mu4 = "/soc/mailbox@4ac90000";
		cameramix_mu5 = "/soc/mailbox@4aca0000";
		cameramix_mu6 = "/soc/mailbox@4acb0000";
		cameramix_mu7 = "/soc/mailbox@4acc0000";
		cameramix_mu8 = "/soc/mailbox@4acd0000";
		cameramix_mu9 = "/soc/mailbox@4ace0000";
		ocram_c_config = "/soc/syscon@4add0000";
		ocram_c = "/soc/ocram@4af80000";
		isp_fw_core = "/soc/remoteproc";
		mipi_dsi = "/soc/dsi@4acf0000";
		mipi_dsi_to_display_pixel_link0 = "/soc/dsi@4acf0000/ports/port@0/endpoint@0";
		mipi_dsi_to_display_pixel_link1 = "/soc/dsi@4acf0000/ports/port@0/endpoint@1";
		display_stream_csr = "/soc/syscon@4ad00000";
		display_master_csr = "/soc/syscon@4ad10000";
		mux = "/soc/syscon@4ad10000/mux-controller";
		mipi_dsi_intf = "/soc/syscon@4acf0000";
		combo_phy_csr = "/soc/syscon@4ad20000";
		dphy_rx = "/soc/syscon@4ad20000/dphy-rx@0";
		combo_rx = "/soc/syscon@4ad20000/combo-rx@100";
		mipi_tx_phy_csr = "/soc/syscon@4ad20100";
		mipi_csi0 = "/soc/csi@4ad30000";
		mipi_csi1 = "/soc/csi@4ad40000";
		isi = "/soc/isi@4ad50000";
		neoisp0 = "/soc/isp@4ae00000";
		dispmix_csr = "/soc/syscon@4b010000";
		display_pixel_link = "/soc/syscon@4b010000/bridge@8";
		display_pixel_link0_to_pixel_interleaver_disp0 = "/soc/syscon@4b010000/bridge@8/ports/port@0/endpoint";
		display_pixel_link1_to_pixel_interleaver_disp1 = "/soc/syscon@4b010000/bridge@8/ports/port@1/endpoint";
		display_pixel_link0_to_mipi_dsi = "/soc/syscon@4b010000/bridge@8/ports/port@2/endpoint@0";
		display_pixel_link0_to_ldb_ch0 = "/soc/syscon@4b010000/bridge@8/ports/port@2/endpoint@1";
		display_pixel_link1_to_mipi_dsi = "/soc/syscon@4b010000/bridge@8/ports/port@3/endpoint@0";
		display_pixel_link1_to_ldb_ch1 = "/soc/syscon@4b010000/bridge@8/ports/port@3/endpoint@1";
		displaymix_irqsteer = "/soc/interrupt-controller@4b0b0000";
		lvds_csr = "/soc/syscon@4b0c0000";
		ldb = "/soc/syscon@4b0c0000/ldb@4";
		ldb_ch0_to_display_pixel_link0 = "/soc/syscon@4b0c0000/ldb@4/channel@0/port@0/endpoint";
		ldb_ch1_to_display_pixel_link1 = "/soc/syscon@4b0c0000/ldb@4/channel@1/port@0/endpoint";
		lvds1_out = "/soc/syscon@4b0c0000/ldb@4/channel@1/port@1/endpoint";
		ldb0_phy = "/soc/syscon@4b0c0000/phy@8";
		ldb0_phy1 = "/soc/syscon@4b0c0000/phy@8/port@0";
		ldb1_phy = "/soc/syscon@4b0c0000/phy@c";
		ldb1_phy1 = "/soc/syscon@4b0c0000/phy@c/port@0";
		pixel_interleaver = "/soc/bridge@4b0d0000";
		pixel_interleaver_disp0_to_dpu_disp0 = "/soc/bridge@4b0d0000/channel@0/port@0/endpoint";
		pixel_interleaver_disp0_to_display_pixel_link0 = "/soc/bridge@4b0d0000/channel@0/port@1/endpoint";
		pixel_interleaver_disp1_to_dpu_disp1 = "/soc/bridge@4b0d0000/channel@1/port@0/endpoint";
		pixel_interleaver_disp1_to_display_pixel_link1 = "/soc/bridge@4b0d0000/channel@1/port@1/endpoint";
		dpu = "/soc/display-controller@4b400000";
		dpu_disp0_to_pixel_interleaver_disp0 = "/soc/display-controller@4b400000/ports/port@0/endpoint";
		dpu_disp1_to_pixel_interleaver_disp1 = "/soc/display-controller@4b400000/ports/port@1/endpoint";
		usb3 = "/soc/usb@4c010010";
		usb3_dwc3 = "/soc/usb@4c010010/usb@4c100000";
		usb3_data_hs = "/soc/usb@4c010010/usb@4c100000/port/endpoint";
		hsio_blk_ctl = "/soc/syscon@4c0100c0";
		usb3_phy = "/soc/phy@4c1f0040";
		usb3_data_ss = "/soc/phy@4c1f0040/port/endpoint";
		usb2 = "/soc/usb@4c200000";
		usbmisc = "/soc/usbmisc@4c200200";
		pcie0 = "/soc/pcie@4c300000";
		pcie0_ep = "/soc/pcie-ep@4c300000";
		pcie1 = "/soc/pcie@4c380000";
		pcie1_ep = "/soc/pcie-ep@4c380000";
		vpu_blk_ctrl = "/soc/clock-controller@4c410000";
		jpegdec = "/soc/jpegdec@4c500000";
		jpegenc = "/soc/jpegenc@4c550000";
		netcmix_blk_ctrl = "/soc/syscon@4c810000";
		sai2 = "/soc/sai@4c880000";
		netc_blk_ctrl = "/soc/system-controller@4cde0000";
		netc_bus0 = "/soc/system-controller@4cde0000/pcie@4ca00000";
		enetc_port0 = "/soc/system-controller@4cde0000/pcie@4ca00000/ethernet@0,0";
		enetc_port1 = "/soc/system-controller@4cde0000/pcie@4ca00000/ethernet@8,0";
		enetc_port2 = "/soc/system-controller@4cde0000/pcie@4ca00000/ethernet@10,0";
		netc_timer = "/soc/system-controller@4cde0000/pcie@4ca00000/ethernet@18,0";
		netc_bus1 = "/soc/system-controller@4cde0000/pcie@4cb00000";
		netc_emdio = "/soc/system-controller@4cde0000/pcie@4cb00000/mdio@0,0";
		ethphy0 = "/soc/system-controller@4cde0000/pcie@4cb00000/mdio@0,0/ethernet-phy@1";
		ethphy1 = "/soc/system-controller@4cde0000/pcie@4cb00000/mdio@0,0/ethernet-phy@2";
		mali = "/soc/gpu@4d900000";
		simple_power = "/soc/gpu@4d900000/power_model@0";
		ipa_power = "/soc/gpu@4d900000/power_model@1";
		vpu0 = "/soc/vpu@4c480000";
		vpu1 = "/soc/vpu@4c490000";
		vpu2 = "/soc/vpu@4c4a0000";
		vpu3 = "/soc/vpu@4c4b0000";
		vpuctrl = "/soc/vpu-ctrl@4c4c0000";
		neutron_core = "/soc/imx95-neutron-remoteproc@4ab00000";
		neutron = "/soc/imx95-neutron@4ab00004";
		ele_if0 = "/secure-enclave-0";
		v2x_dbg = "/secure-enclave-1";
		v2x_sv0 = "/secure-enclave-2";
		v2x_she = "/secure-enclave-3";
		v2x_sg0 = "/secure-enclave-4";
		v2x_sg1 = "/secure-enclave-5";
		bt_sco_codec = "/bt-sco-codec";
		dmic = "/dmic";
		hdmi_connector_in = "/hdmi-connector/port/endpoint";
		linux_cma = "/reserved-memory/linux,cma";
		vpu_boot = "/reserved-memory/vpu_boot@a0000000";
		vdev0vring0 = "/reserved-memory/vdev0vring0@88000000";
		vdev0vring1 = "/reserved-memory/vdev0vring1@88008000";
		vdev1vring0 = "/reserved-memory/vdev1vring0@88010000";
		vdev1vring1 = "/reserved-memory/vdev1vring1@88018000";
		rsc_table = "/reserved-memory/rsc-table@88220000";
		vdevbuffer = "/reserved-memory/vdevbuffer@88020000";
		ele_reserved = "/reserved-memory/ele-reserved@a4120000";
		reg_1p8v = "/regulator-1p8v";
		reg_3p3v = "/regulator-3p3v";
		reg_5p0v = "/regulator-5p0v";
		reg_can_stby = "/regulator-can-stby";
		reg_ext_3v3 = "/regulator-ext-3v3";
		reg_ext_5v = "/regulator-ext-5v";
		reg_ext_12v = "/regulator-ext-12v";
		reg_usdhc2_vmmc = "/regulator-usdhc2";
		reg_usb_vbus = "/regulator-vbus";
		usdhc3_pwrseq = "/usdhc3-pwrseq";
		reg_usdhc3_vmmc = "/regulator-usdhc3";
		reg_vref_1v8 = "/regulator-adc-vref";
		reg_m2_ekey_pwr = "/regulator-m2-pwr";
		reg_m2_mkey_pwr = "/regulator-m2-mkey-pwr";
		cm7 = "/imx95-cm7";
		btcpu = "/sound-bt-sco/simple-audio-card,cpu";
	};
};
